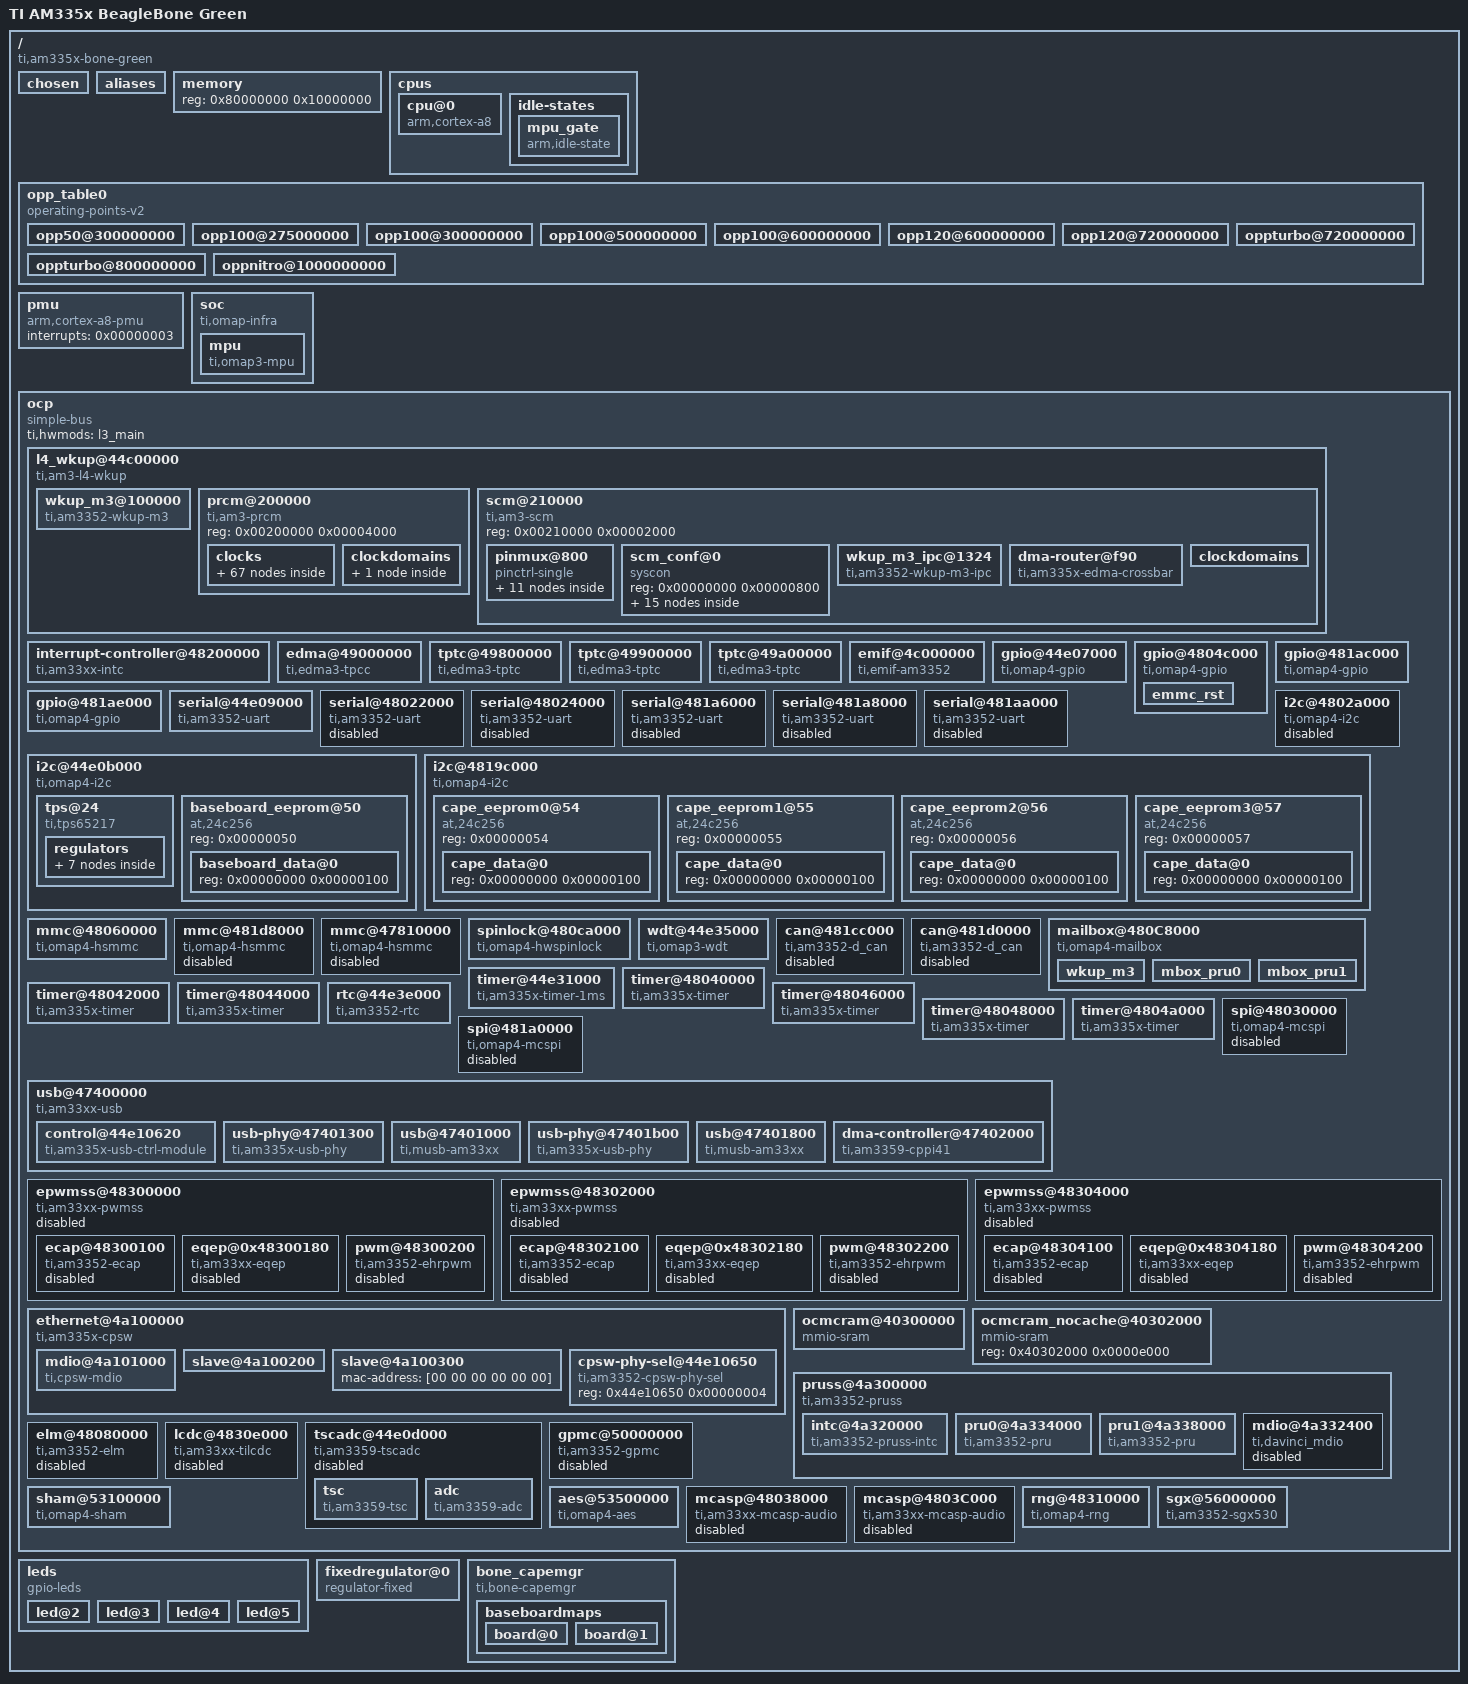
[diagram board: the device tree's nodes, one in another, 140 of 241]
/dts-v1/;
// magic:		0xd00dfeed
// totalsize:		0xd51f (54559)
// off_dt_struct:	0x38
// off_dt_strings:	0xc508
// off_mem_rsvmap:	0x28
// version:		17
// last_comp_version:	16
// boot_cpuid_phys:	0x0
// size_dt_strings:	0x1017
// size_dt_struct:	0xc4d0

/ {
    #address-cells = <0x00000001>;
    #size-cells = <0x00000001>;
    compatible = "ti,am335x-bone-green", "ti,am335x-bone-black", "ti,am335x-bone", "ti,am33xx";
    interrupt-parent = <0x00000001>;
    model = "TI AM335x BeagleBone Green";
    chosen {
    };
    aliases {
        i2c0 = "/ocp/i2c@44e0b000";
        i2c1 = "/ocp/i2c@4802a000";
        i2c2 = "/ocp/i2c@4819c000";
        serial0 = "/ocp/serial@44e09000";
        serial1 = "/ocp/serial@48022000";
        serial2 = "/ocp/serial@48024000";
        serial3 = "/ocp/serial@481a6000";
        serial4 = "/ocp/serial@481a8000";
        serial5 = "/ocp/serial@481aa000";
        d_can0 = "/ocp/can@481cc000";
        d_can1 = "/ocp/can@481d0000";
        usb0 = "/ocp/usb@47400000/usb@47401000";
        usb1 = "/ocp/usb@47400000/usb@47401800";
        phy0 = "/ocp/usb@47400000/usb-phy@47401300";
        phy1 = "/ocp/usb@47400000/usb-phy@47401b00";
        ethernet0 = "/ocp/ethernet@4a100000/slave@4a100200";
        ethernet1 = "/ocp/ethernet@4a100000/slave@4a100300";
    };
    memory {
        device_type = "memory";
        reg = <0x80000000 0x10000000>;
    };
    cpus {
        #address-cells = <0x00000001>;
        #size-cells = <0x00000000>;
        cpu@0 {
            compatible = "arm,cortex-a8";
            enable-method = "ti,am3352";
            device_type = "cpu";
            reg = <0x00000000>;
            operating-points-v2 = <0x00000002>;
            ti,syscon-efuse = <0x00000003 0x000007fc 0x00001fff 0x00000000>;
            ti,syscon-rev = <0x00000003 0x00000600>;
            clocks = <0x00000004>;
            clock-names = "cpu";
            clock-latency = <0x000493e0>;
            cpu-idle-states = <0x00000005>;
            cpu0-supply = <0x00000006>;
        };
        idle-states {
            mpu_gate {
                compatible = "arm,idle-state";
                entry-latency-us = <0x00000028>;
                exit-latency-us = <0x0000005a>;
                min-residency-us = <0x0000012c>;
                ti,idle-wkup-m3;
                linux,phandle = <0x00000005>;
                phandle = <0x00000005>;
            };
        };
    };
    opp_table0 {
        compatible = "operating-points-v2";
        linux,phandle = <0x00000002>;
        phandle = <0x00000002>;
        opp50@300000000 {
            opp-hz = <0x00000000 0x11e1a300>;
            opp-microvolt = <0x000e7ef0 0x000e34b8 0x000ec928>;
            opp-supported-hw = <0x00000006 0x00000010>;
            opp-suspend;
        };
        opp100@275000000 {
            opp-hz = <0x00000000 0x10642ac0>;
            opp-microvolt = <0x0010c8e0 0x001072f0 0x00111ed0>;
            opp-supported-hw = <0x00000001 0x000000ff>;
            opp-suspend;
        };
        opp100@300000000 {
            opp-hz = <0x00000000 0x11e1a300>;
            opp-microvolt = <0x0010c8e0 0x001072f0 0x00111ed0>;
            opp-supported-hw = <0x00000006 0x00000020>;
            opp-suspend;
        };
        opp100@500000000 {
            opp-hz = <0x00000000 0x1dcd6500>;
            opp-microvolt = <0x0010c8e0 0x001072f0 0x00111ed0>;
            opp-supported-hw = <0x00000001 0x0000ffff>;
        };
        opp100@600000000 {
            opp-hz = <0x00000000 0x23c34600>;
            opp-microvolt = <0x0010c8e0 0x001072f0 0x00111ed0>;
            opp-supported-hw = <0x00000006 0x00000040>;
        };
        opp120@600000000 {
            opp-hz = <0x00000000 0x23c34600>;
            opp-microvolt = <0x00124f80 0x0011f1c0 0x0012ad40>;
            opp-supported-hw = <0x00000001 0x0000ffff>;
        };
        opp120@720000000 {
            opp-hz = <0x00000000 0x2aea5400>;
            opp-microvolt = <0x00124f80 0x0011f1c0 0x0012ad40>;
            opp-supported-hw = <0x00000006 0x00000080>;
        };
        oppturbo@720000000 {
            opp-hz = <0x00000000 0x2aea5400>;
            opp-microvolt = <0x001339e0 0x0012d770 0x00139c50>;
            opp-supported-hw = <0x00000001 0x0000ffff>;
        };
        oppturbo@800000000 {
            opp-hz = <0x00000000 0x2faf0800>;
            opp-microvolt = <0x001339e0 0x0012d770 0x00139c50>;
            opp-supported-hw = <0x00000006 0x00000100>;
        };
        oppnitro@1000000000 {
            opp-hz = <0x00000000 0x3b9aca00>;
            opp-microvolt = <0x001437c8 0x0013d044 0x00149f4c>;
            opp-supported-hw = <0x00000006 0x00000100>;
        };
    };
    pmu {
        compatible = "arm,cortex-a8-pmu";
        interrupts = <0x00000003>;
    };
    soc {
        compatible = "ti,omap-infra";
        mpu {
            compatible = "ti,omap3-mpu";
            ti,hwmods = "mpu";
            sram = <0x00000007>;
        };
    };
    ocp {
        compatible = "simple-bus";
        #address-cells = <0x00000001>;
        #size-cells = <0x00000001>;
        ranges;
        ti,hwmods = "l3_main";
        linux,phandle = <0x00000051>;
        phandle = <0x00000051>;
        l4_wkup@44c00000 {
            compatible = "ti,am3-l4-wkup", "simple-bus";
            #address-cells = <0x00000001>;
            #size-cells = <0x00000001>;
            ranges = <0x00000000 0x44c00000 0x00280000>;
            linux,phandle = <0x00000052>;
            phandle = <0x00000052>;
            wkup_m3@100000 {
                compatible = "ti,am3352-wkup-m3";
                reg = <0x00100000 0x00004000 0x00180000 0x00002000>;
                reg-names = "umem", "dmem";
                ti,hwmods = "wkup_m3";
                ti,pm-firmware = "am335x-pm-firmware.elf";
                linux,phandle = <0x00000029>;
                phandle = <0x00000029>;
            };
            prcm@200000 {
                compatible = "ti,am3-prcm";
                reg = <0x00200000 0x00004000>;
                linux,phandle = <0x00000053>;
                phandle = <0x00000053>;
                clocks {
                    #address-cells = <0x00000001>;
                    #size-cells = <0x00000000>;
                    linux,phandle = <0x00000054>;
                    phandle = <0x00000054>;
                    clk_32768_ck {
                        #clock-cells = <0x00000000>;
                        compatible = "fixed-clock";
                        clock-frequency = <0x00008000>;
                        linux,phandle = <0x00000018>;
                        phandle = <0x00000018>;
                    };
                    clk_rc32k_ck {
                        #clock-cells = <0x00000000>;
                        compatible = "fixed-clock";
                        clock-frequency = <0x00007d00>;
                        linux,phandle = <0x00000017>;
                        phandle = <0x00000017>;
                    };
                    virt_19200000_ck {
                        #clock-cells = <0x00000000>;
                        compatible = "fixed-clock";
                        clock-frequency = <0x0124f800>;
                        linux,phandle = <0x00000024>;
                        phandle = <0x00000024>;
                    };
                    virt_24000000_ck {
                        #clock-cells = <0x00000000>;
                        compatible = "fixed-clock";
                        clock-frequency = <0x016e3600>;
                        linux,phandle = <0x00000025>;
                        phandle = <0x00000025>;
                    };
                    virt_25000000_ck {
                        #clock-cells = <0x00000000>;
                        compatible = "fixed-clock";
                        clock-frequency = <0x017d7840>;
                        linux,phandle = <0x00000026>;
                        phandle = <0x00000026>;
                    };
                    virt_26000000_ck {
                        #clock-cells = <0x00000000>;
                        compatible = "fixed-clock";
                        clock-frequency = <0x018cba80>;
                        linux,phandle = <0x00000027>;
                        phandle = <0x00000027>;
                    };
                    tclkin_ck {
                        #clock-cells = <0x00000000>;
                        compatible = "fixed-clock";
                        clock-frequency = <0x00b71b00>;
                        linux,phandle = <0x00000016>;
                        phandle = <0x00000016>;
                    };
                    dpll_core_ck {
                        #clock-cells = <0x00000000>;
                        compatible = "ti,am3-dpll-core-clock";
                        clocks = <0x00000008 0x00000008>;
                        reg = <0x00000490 0x0000045c 0x00000468>;
                        linux,phandle = <0x00000009>;
                        phandle = <0x00000009>;
                    };
                    dpll_core_x2_ck {
                        #clock-cells = <0x00000000>;
                        compatible = "ti,am3-dpll-x2-clock";
                        clocks = <0x00000009>;
                        linux,phandle = <0x0000000a>;
                        phandle = <0x0000000a>;
                    };
                    dpll_core_m4_ck {
                        #clock-cells = <0x00000000>;
                        compatible = "ti,divider-clock";
                        clocks = <0x0000000a>;
                        ti,max-div = <0x0000001f>;
                        reg = <0x00000480>;
                        ti,index-starts-at-one;
                        linux,phandle = <0x00000012>;
                        phandle = <0x00000012>;
                    };
                    dpll_core_m5_ck {
                        #clock-cells = <0x00000000>;
                        compatible = "ti,divider-clock";
                        clocks = <0x0000000a>;
                        ti,max-div = <0x0000001f>;
                        reg = <0x00000484>;
                        ti,index-starts-at-one;
                        linux,phandle = <0x0000001a>;
                        phandle = <0x0000001a>;
                    };
                    dpll_core_m6_ck {
                        #clock-cells = <0x00000000>;
                        compatible = "ti,divider-clock";
                        clocks = <0x0000000a>;
                        ti,max-div = <0x0000001f>;
                        reg = <0x000004d8>;
                        ti,index-starts-at-one;
                        linux,phandle = <0x00000055>;
                        phandle = <0x00000055>;
                    };
                    dpll_mpu_ck {
                        #clock-cells = <0x00000000>;
                        compatible = "ti,am3-dpll-clock";
                        clocks = <0x00000008 0x00000008>;
                        reg = <0x00000488 0x00000420 0x0000042c>;
                        linux,phandle = <0x00000004>;
                        phandle = <0x00000004>;
                    };
                    dpll_mpu_m2_ck {
                        #clock-cells = <0x00000000>;
                        compatible = "ti,divider-clock";
                        clocks = <0x00000004>;
                        ti,max-div = <0x0000001f>;
                        reg = <0x000004a8>;
                        ti,index-starts-at-one;
                        linux,phandle = <0x00000056>;
                        phandle = <0x00000056>;
                    };
                    dpll_ddr_ck {
                        #clock-cells = <0x00000000>;
                        compatible = "ti,am3-dpll-no-gate-clock";
                        clocks = <0x00000008 0x00000008>;
                        reg = <0x00000494 0x00000434 0x00000440>;
                        linux,phandle = <0x0000000b>;
                        phandle = <0x0000000b>;
                    };
                    dpll_ddr_m2_ck {
                        #clock-cells = <0x00000000>;
                        compatible = "ti,divider-clock";
                        clocks = <0x0000000b>;
                        ti,max-div = <0x0000001f>;
                        reg = <0x000004a0>;
                        ti,index-starts-at-one;
                        linux,phandle = <0x0000000c>;
                        phandle = <0x0000000c>;
                    };
                    dpll_ddr_m2_div2_ck {
                        #clock-cells = <0x00000000>;
                        compatible = "fixed-factor-clock";
                        clocks = <0x0000000c>;
                        clock-mult = <0x00000001>;
                        clock-div = <0x00000002>;
                        linux,phandle = <0x00000057>;
                        phandle = <0x00000057>;
                    };
                    dpll_disp_ck {
                        #clock-cells = <0x00000000>;
                        compatible = "ti,am3-dpll-no-gate-clock";
                        clocks = <0x00000008 0x00000008>;
                        reg = <0x00000498 0x00000448 0x00000454>;
                        linux,phandle = <0x0000000d>;
                        phandle = <0x0000000d>;
                    };
                    dpll_disp_m2_ck {
                        #clock-cells = <0x00000000>;
                        compatible = "ti,divider-clock";
                        clocks = <0x0000000d>;
                        ti,max-div = <0x0000001f>;
                        reg = <0x000004a4>;
                        ti,index-starts-at-one;
                        ti,set-rate-parent;
                        linux,phandle = <0x00000014>;
                        phandle = <0x00000014>;
                    };
                    dpll_per_ck {
                        #clock-cells = <0x00000000>;
                        compatible = "ti,am3-dpll-no-gate-j-type-clock";
                        clocks = <0x00000008 0x00000008>;
                        reg = <0x0000048c 0x00000470 0x0000049c>;
                        linux,phandle = <0x0000000e>;
                        phandle = <0x0000000e>;
                    };
                    dpll_per_m2_ck {
                        #clock-cells = <0x00000000>;
                        compatible = "ti,divider-clock";
                        clocks = <0x0000000e>;
                        ti,max-div = <0x0000001f>;
                        reg = <0x000004ac>;
                        ti,index-starts-at-one;
                        linux,phandle = <0x0000000f>;
                        phandle = <0x0000000f>;
                    };
                    dpll_per_m2_div4_wkupdm_ck {
                        #clock-cells = <0x00000000>;
                        compatible = "fixed-factor-clock";
                        clocks = <0x0000000f>;
                        clock-mult = <0x00000001>;
                        clock-div = <0x00000004>;
                        linux,phandle = <0x00000058>;
                        phandle = <0x00000058>;
                    };
                    dpll_per_m2_div4_ck {
                        #clock-cells = <0x00000000>;
                        compatible = "fixed-factor-clock";
                        clocks = <0x0000000f>;
                        clock-mult = <0x00000001>;
                        clock-div = <0x00000004>;
                        linux,phandle = <0x00000059>;
                        phandle = <0x00000059>;
                    };
                    cefuse_fck {
                        #clock-cells = <0x00000000>;
                        compatible = "ti,gate-clock";
                        clocks = <0x00000008>;
                        ti,bit-shift = <0x00000001>;
                        reg = <0x00000a20>;
                        linux,phandle = <0x0000005a>;
                        phandle = <0x0000005a>;
                    };
                    clk_24mhz {
                        #clock-cells = <0x00000000>;
                        compatible = "fixed-factor-clock";
                        clocks = <0x0000000f>;
                        clock-mult = <0x00000001>;
                        clock-div = <0x00000008>;
                        linux,phandle = <0x00000010>;
                        phandle = <0x00000010>;
                    };
                    clkdiv32k_ck {
                        #clock-cells = <0x00000000>;
                        compatible = "fixed-factor-clock";
                        clocks = <0x00000010>;
                        clock-mult = <0x00000001>;
                        clock-div = <0x000002dc>;
                        linux,phandle = <0x00000011>;
                        phandle = <0x00000011>;
                    };
                    clkdiv32k_ick {
                        #clock-cells = <0x00000000>;
                        compatible = "ti,gate-clock";
                        clocks = <0x00000011>;
                        ti,bit-shift = <0x00000001>;
                        reg = <0x0000014c>;
                        linux,phandle = <0x00000015>;
                        phandle = <0x00000015>;
                    };
                    l3_gclk {
                        #clock-cells = <0x00000000>;
                        compatible = "fixed-factor-clock";
                        clocks = <0x00000012>;
                        clock-mult = <0x00000001>;
                        clock-div = <0x00000001>;
                        linux,phandle = <0x00000013>;
                        phandle = <0x00000013>;
                    };
                    pruss_ocp_gclk {
                        #clock-cells = <0x00000000>;
                        compatible = "ti,mux-clock";
                        clocks = <0x00000013 0x00000014>;
                        reg = <0x00000530>;
                        linux,phandle = <0x0000005b>;
                        phandle = <0x0000005b>;
                    };
                    mmu_fck {
                        #clock-cells = <0x00000000>;
                        compatible = "ti,gate-clock";
                        clocks = <0x00000012>;
                        ti,bit-shift = <0x00000001>;
                        reg = <0x00000914>;
                        linux,phandle = <0x0000005c>;
                        phandle = <0x0000005c>;
                    };
                    timer1_fck {
                        #clock-cells = <0x00000000>;
                        compatible = "ti,mux-clock";
                        clocks = <0x00000008 0x00000015 0x00000016 0x00000017 0x00000018>;
                        reg = <0x00000528>;
                        linux,phandle = <0x0000005d>;
                        phandle = <0x0000005d>;
                    };
                    timer2_fck {
                        #clock-cells = <0x00000000>;
                        compatible = "ti,mux-clock";
                        clocks = <0x00000016 0x00000008 0x00000015>;
                        reg = <0x00000508>;
                        linux,phandle = <0x0000005e>;
                        phandle = <0x0000005e>;
                    };
                    timer3_fck {
                        #clock-cells = <0x00000000>;
                        compatible = "ti,mux-clock";
                        clocks = <0x00000016 0x00000008 0x00000015>;
                        reg = <0x0000050c>;
                        linux,phandle = <0x0000005f>;
                        phandle = <0x0000005f>;
                    };
                    timer4_fck {
                        #clock-cells = <0x00000000>;
                        compatible = "ti,mux-clock";
                        clocks = <0x00000016 0x00000008 0x00000015>;
                        reg = <0x00000510>;
                        linux,phandle = <0x00000060>;
                        phandle = <0x00000060>;
                    };
                    timer5_fck {
                        #clock-cells = <0x00000000>;
                        compatible = "ti,mux-clock";
                        clocks = <0x00000016 0x00000008 0x00000015>;
                        reg = <0x00000518>;
                        linux,phandle = <0x00000061>;
                        phandle = <0x00000061>;
                    };
                    timer6_fck {
                        #clock-cells = <0x00000000>;
                        compatible = "ti,mux-clock";
                        clocks = <0x00000016 0x00000008 0x00000015>;
                        reg = <0x0000051c>;
                        linux,phandle = <0x00000062>;
                        phandle = <0x00000062>;
                    };
                    timer7_fck {
                        #clock-cells = <0x00000000>;
                        compatible = "ti,mux-clock";
                        clocks = <0x00000016 0x00000008 0x00000015>;
                        reg = <0x00000504>;
                        linux,phandle = <0x00000063>;
                        phandle = <0x00000063>;
                    };
                    usbotg_fck {
                        #clock-cells = <0x00000000>;
                        compatible = "ti,gate-clock";
                        clocks = <0x0000000e>;
                        ti,bit-shift = <0x00000008>;
                        reg = <0x0000047c>;
                        linux,phandle = <0x00000064>;
                        phandle = <0x00000064>;
                    };
                    dpll_core_m4_div2_ck {
                        #clock-cells = <0x00000000>;
                        compatible = "fixed-factor-clock";
                        clocks = <0x00000012>;
                        clock-mult = <0x00000001>;
                        clock-div = <0x00000002>;
                        linux,phandle = <0x00000019>;
                        phandle = <0x00000019>;
                    };
                    ieee5000_fck {
                        #clock-cells = <0x00000000>;
                        compatible = "ti,gate-clock";
                        clocks = <0x00000019>;
                        ti,bit-shift = <0x00000001>;
                        reg = <0x000000e4>;
                        linux,phandle = <0x00000065>;
                        phandle = <0x00000065>;
                    };
                    wdt1_fck {
                        #clock-cells = <0x00000000>;
                        compatible = "ti,mux-clock";
                        clocks = <0x00000017 0x00000015>;
                        reg = <0x00000538>;
                        linux,phandle = <0x00000066>;
                        phandle = <0x00000066>;
                    };
                    l4_rtc_gclk {
                        #clock-cells = <0x00000000>;
                        compatible = "fixed-factor-clock";
                        clocks = <0x00000012>;
                        clock-mult = <0x00000001>;
                        clock-div = <0x00000002>;
                        linux,phandle = <0x00000067>;
                        phandle = <0x00000067>;
                    };
                    l4hs_gclk {
                        #clock-cells = <0x00000000>;
                        compatible = "fixed-factor-clock";
                        clocks = <0x00000012>;
                        clock-mult = <0x00000001>;
                        clock-div = <0x00000001>;
                        linux,phandle = <0x00000068>;
                        phandle = <0x00000068>;
                    };
                    l3s_gclk {
                        #clock-cells = <0x00000000>;
                        compatible = "fixed-factor-clock";
                        clocks = <0x00000019>;
                        clock-mult = <0x00000001>;
                        clock-div = <0x00000001>;
                        linux,phandle = <0x00000069>;
                        phandle = <0x00000069>;
                    };
                    l4fw_gclk {
                        #clock-cells = <0x00000000>;
                        compatible = "fixed-factor-clock";
                        clocks = <0x00000019>;
                        clock-mult = <0x00000001>;
                        clock-div = <0x00000001>;
                        linux,phandle = <0x0000006a>;
                        phandle = <0x0000006a>;
                    };
                    l4ls_gclk {
                        #clock-cells = <0x00000000>;
                        compatible = "fixed-factor-clock";
                        clocks = <0x00000019>;
                        clock-mult = <0x00000001>;
                        clock-div = <0x00000001>;
                        linux,phandle = <0x00000028>;
                        phandle = <0x00000028>;
                    };
                    sysclk_div_ck {
                        #clock-cells = <0x00000000>;
                        compatible = "fixed-factor-clock";
                        clocks = <0x00000012>;
                        clock-mult = <0x00000001>;
                        clock-div = <0x00000001>;
                        linux,phandle = <0x0000006b>;
                        phandle = <0x0000006b>;
                    };
                    cpsw_125mhz_gclk {
                        #clock-cells = <0x00000000>;
                        compatible = "fixed-factor-clock";
                        clocks = <0x0000001a>;
                        clock-mult = <0x00000001>;
                        clock-div = <0x00000002>;
                        linux,phandle = <0x00000040>;
                        phandle = <0x00000040>;
                    };
                    cpsw_cpts_rft_clk {
                        #clock-cells = <0x00000000>;
                        compatible = "ti,mux-clock";
                        clocks = <0x0000001a 0x00000012>;
                        reg = <0x00000520>;
                        linux,phandle = <0x00000041>;
                        phandle = <0x00000041>;
                    };
                    gpio0_dbclk_mux_ck {
                        #clock-cells = <0x00000000>;
                        compatible = "ti,mux-clock";
                        clocks = <0x00000017 0x00000018 0x00000015>;
                        reg = <0x0000053c>;
                        linux,phandle = <0x0000001b>;
                        phandle = <0x0000001b>;
                    };
                    gpio0_dbclk {
                        #clock-cells = <0x00000000>;
                        compatible = "ti,gate-clock";
                        clocks = <0x0000001b>;
                        ti,bit-shift = <0x00000012>;
                        reg = <0x00000408>;
                        linux,phandle = <0x0000006c>;
                        phandle = <0x0000006c>;
                    };
                    gpio1_dbclk {
                        #clock-cells = <0x00000000>;
                        compatible = "ti,gate-clock";
                        clocks = <0x00000015>;
                        ti,bit-shift = <0x00000012>;
                        reg = <0x000000ac>;
                        linux,phandle = <0x0000006d>;
                        phandle = <0x0000006d>;
                    };
                    gpio2_dbclk {
                        #clock-cells = <0x00000000>;
                        compatible = "ti,gate-clock";
                        clocks = <0x00000015>;
                        ti,bit-shift = <0x00000012>;
                        reg = <0x000000b0>;
                        linux,phandle = <0x0000006e>;
                        phandle = <0x0000006e>;
                    };
                    gpio3_dbclk {
                        #clock-cells = <0x00000000>;
                        compatible = "ti,gate-clock";
                        clocks = <0x00000015>;
                        ti,bit-shift = <0x00000012>;
                        reg = <0x000000b4>;
                        linux,phandle = <0x0000006f>;
                        phandle = <0x0000006f>;
                    };
                    lcd_gclk {
                        #clock-cells = <0x00000000>;
                        compatible = "ti,mux-clock";
                        clocks = <0x00000014 0x0000001a 0x0000000f>;
                        reg = <0x00000534>;
                        ti,set-rate-parent;
                        linux,phandle = <0x0000001d>;
                        phandle = <0x0000001d>;
                    };
                    mmc_clk {
                        #clock-cells = <0x00000000>;
                        compatible = "fixed-factor-clock";
                        clocks = <0x0000000f>;
                        clock-mult = <0x00000001>;
                        clock-div = <0x00000002>;
                        linux,phandle = <0x00000070>;
                        phandle = <0x00000070>;
                    };
                    gfx_fclk_clksel_ck {
                        #clock-cells = <0x00000000>;
                        compatible = "ti,mux-clock";
                        clocks = <0x00000012 0x0000000f>;
                        ti,bit-shift = <0x00000001>;
                        reg = <0x0000052c>;
                        linux,phandle = <0x0000001c>;
                        phandle = <0x0000001c>;
                    };
                    gfx_fck_div_ck {
                        #clock-cells = <0x00000000>;
                        compatible = "ti,divider-clock";
                        clocks = <0x0000001c>;
                        reg = <0x0000052c>;
                        ti,max-div = <0x00000002>;
                        linux,phandle = <0x00000048>;
                        phandle = <0x00000048>;
                    };
                    sysclkout_pre_ck {
                        #clock-cells = <0x00000000>;
                        compatible = "ti,mux-clock";
                        clocks = <0x00000018 0x00000013 0x0000000c 0x0000000f 0x0000001d>;
                        reg = <0x00000700>;
                        linux,phandle = <0x0000001e>;
                        phandle = <0x0000001e>;
                    };
                    clkout2_div_ck {
                        #clock-cells = <0x00000000>;
                        compatible = "ti,divider-clock";
                        clocks = <0x0000001e>;
                        ti,bit-shift = <0x00000003>;
                        ti,max-div = <0x00000008>;
                        reg = <0x00000700>;
                        linux,phandle = <0x00000023>;
                        phandle = <0x00000023>;
                    };
                    dbg_sysclk_ck {
                        #clock-cells = <0x00000000>;
                        compatible = "ti,gate-clock";
                        clocks = <0x00000008>;
                        ti,bit-shift = <0x00000013>;
                        reg = <0x00000414>;
                        linux,phandle = <0x0000001f>;
                        phandle = <0x0000001f>;
                    };
                    dbg_clka_ck {
                        #clock-cells = <0x00000000>;
                        compatible = "ti,gate-clock";
                        clocks = <0x00000012>;
                        ti,bit-shift = <0x0000001e>;
                        reg = <0x00000414>;
                        linux,phandle = <0x00000020>;
                        phandle = <0x00000020>;
                    };
                    stm_pmd_clock_mux_ck {
                        #clock-cells = <0x00000000>;
                        compatible = "ti,mux-clock";
                        clocks = <0x0000001f 0x00000020>;
                        ti,bit-shift = <0x00000016>;
                        reg = <0x00000414>;
                        linux,phandle = <0x00000021>;
                        phandle = <0x00000021>;
                    };
                    trace_pmd_clk_mux_ck {
                        #clock-cells = <0x00000000>;
                        compatible = "ti,mux-clock";
                        clocks = <0x0000001f 0x00000020>;
                        ti,bit-shift = <0x00000014>;
                        reg = <0x00000414>;
                        linux,phandle = <0x00000022>;
                        phandle = <0x00000022>;
                    };
                    stm_clk_div_ck {
                        #clock-cells = <0x00000000>;
                        compatible = "ti,divider-clock";
                        clocks = <0x00000021>;
                        ti,bit-shift = <0x0000001b>;
                        ti,max-div = <0x00000040>;
                        reg = <0x00000414>;
                        ti,index-power-of-two;
                        linux,phandle = <0x00000071>;
                        phandle = <0x00000071>;
                    };
                    trace_clk_div_ck {
                        #clock-cells = <0x00000000>;
                        compatible = "ti,divider-clock";
                        clocks = <0x00000022>;
                        ti,bit-shift = <0x00000018>;
                        ti,max-div = <0x00000040>;
                        reg = <0x00000414>;
                        ti,index-power-of-two;
                        linux,phandle = <0x00000072>;
                        phandle = <0x00000072>;
                    };
                    clkout2_ck {
                        #clock-cells = <0x00000000>;
                        compatible = "ti,gate-clock";
                        clocks = <0x00000023>;
                        ti,bit-shift = <0x00000007>;
                        reg = <0x00000700>;
                        linux,phandle = <0x00000073>;
                        phandle = <0x00000073>;
                    };
                };
                clockdomains {
                    linux,phandle = <0x00000074>;
                    phandle = <0x00000074>;
                    clk_24mhz_clkdm {
                        compatible = "ti,clockdomain";
                        clocks = <0x00000015>;
                        linux,phandle = <0x00000075>;
                        phandle = <0x00000075>;
                    };
                };
            };
            scm@210000 {
                compatible = "ti,am3-scm", "simple-bus";
                reg = <0x00210000 0x00002000>;
                #address-cells = <0x00000001>;
                #size-cells = <0x00000001>;
                ranges = <0x00000000 0x00210000 0x00002000>;
                linux,phandle = <0x00000076>;
                phandle = <0x00000076>;
                pinmux@800 {
                    compatible = "pinctrl-single";
                    reg = <0x00000800 0x00000238>;
                    #address-cells = <0x00000001>;
                    #size-cells = <0x00000000>;
                    pinctrl-single,register-width = <0x00000020>;
                    pinctrl-single,function-mask = <0x0000007f>;
                    linux,phandle = <0x00000077>;
                    phandle = <0x00000077>;
                    user_leds_default {
                        pinctrl-single,pins = <0x00000054 0x00000007 0x00000058 0x00000017 0x0000005c 0x00000007 0x00000060 0x00000017>;
                        linux,phandle = <0x00000049>;
                        phandle = <0x00000049>;
                    };
                    user_leds_sleep {
                        pinctrl-single,pins = <0x00000054 0x00000027 0x00000058 0x00000027 0x0000005c 0x00000027 0x00000060 0x00000027>;
                        linux,phandle = <0x0000004a>;
                        phandle = <0x0000004a>;
                    };
                    pinmux_i2c0_pins {
                        pinctrl-single,pins = <0x00000188 0x00000030 0x0000018c 0x00000030>;
                        linux,phandle = <0x00000031>;
                        phandle = <0x00000031>;
                    };
                    pinmux_i2c2_pins {
                        //pinctrl-single,pins = <0x00000178 0x00000033 0x0000017c 0x00000033>; //whooooops XXX
                        pinctrl-single,pins = <0x00000178 0x00000017 0x0000017c 0x0000002F>; //whooooops XXX
                        linux,phandle = <0x00000032>;
                        phandle = <0x00000032>;
                    };
                    pinmux_uart0_pins {
                        pinctrl-single,pins = <0x00000170 0x00000030 0x00000174 0x00000000>;
                        linux,phandle = <0x00000030>;
                        phandle = <0x00000030>;
                    };
                    cpsw_default {
                        pinctrl-single,pins = <0x00000108 0x00000028 0x0000010c 0x00000028 0x00000110 0x00000030 0x00000114 0x00000000 0x00000118 0x00000030 0x0000011c 0x00000000 0x00000120 0x00000000 0x00000124 0x00000000 0x00000128 0x00000000 0x0000012c 0x00000030 0x00000130 0x00000030 0x00000134 0x00000030 0x00000138 0x00000030 0x0000013c 0x00000030 0x00000140 0x00000030>;
                        linux,phandle = <0x00000042>;
                        phandle = <0x00000042>;
                    };
                    cpsw_sleep {
                        pinctrl-single,pins = <0x00000108 0x00000027 0x0000010c 0x00000027 0x00000110 0x00000027 0x00000114 0x00000027 0x00000118 0x00000027 0x0000011c 0x00000027 0x00000120 0x00000027 0x00000124 0x00000027 0x00000128 0x00000027 0x0000012c 0x00000027 0x00000130 0x00000027 0x00000134 0x00000027 0x00000138 0x00000027 0x0000013c 0x00000027 0x00000140 0x00000027>;
                        linux,phandle = <0x00000043>;
                        phandle = <0x00000043>;
                    };
                    davinci_mdio_default {
                        pinctrl-single,pins = <0x00000148 0x00000030 0x0000014c 0x00000010>;
                        linux,phandle = <0x00000044>;
                        phandle = <0x00000044>;
                    };
                    davinci_mdio_sleep {
                        pinctrl-single,pins = <0x00000148 0x00000027 0x0000014c 0x00000027>;
                        linux,phandle = <0x00000045>;
                        phandle = <0x00000045>;
                    };
                    pinmux_mmc1_pins {
                        pinctrl-single,pins = <0x00000160 0x0000002f>;
                        linux,phandle = <0x00000034>;
                        phandle = <0x00000034>;
                    };
                    pinmux_emmc_pins {
                        pinctrl-single,pins = <0x00000080 0x00000032 0x00000084 0x00000032 0x00000000 0x00000031 0x00000004 0x00000031 0x00000008 0x00000031 0x0000000c 0x00000031 0x00000010 0x00000031 0x00000014 0x00000031 0x00000018 0x00000031 0x0000001c 0x00000031>;
                        linux,phandle = <0x00000078>;
                        phandle = <0x00000078>;
                    };
                };
                scm_conf@0 {
                    compatible = "syscon";
                    reg = <0x00000000 0x00000800>;
                    #address-cells = <0x00000001>;
                    #size-cells = <0x00000001>;
                    linux,phandle = <0x00000003>;
                    phandle = <0x00000003>;
                    clocks {
                        #address-cells = <0x00000001>;
                        #size-cells = <0x00000000>;
                        linux,phandle = <0x00000079>;
                        phandle = <0x00000079>;
                        sys_clkin_ck {
                            #clock-cells = <0x00000000>;
                            compatible = "ti,mux-clock";
                            clocks = <0x00000024 0x00000025 0x00000026 0x00000027>;
                            ti,bit-shift = <0x00000016>;
                            reg = <0x00000040>;
                            linux,phandle = <0x00000008>;
                            phandle = <0x00000008>;
                        };
                        adc_tsc_fck {
                            #clock-cells = <0x00000000>;
                            compatible = "fixed-factor-clock";
                            clocks = <0x00000008>;
                            clock-mult = <0x00000001>;
                            clock-div = <0x00000001>;
                            linux,phandle = <0x0000007a>;
                            phandle = <0x0000007a>;
                        };
                        dcan0_fck {
                            #clock-cells = <0x00000000>;
                            compatible = "fixed-factor-clock";
                            clocks = <0x00000008>;
                            clock-mult = <0x00000001>;
                            clock-div = <0x00000001>;
                            linux,phandle = <0x00000037>;
                            phandle = <0x00000037>;
                        };
                        dcan1_fck {
                            #clock-cells = <0x00000000>;
                            compatible = "fixed-factor-clock";
                            clocks = <0x00000008>;
                            clock-mult = <0x00000001>;
                            clock-div = <0x00000001>;
                            linux,phandle = <0x00000038>;
                            phandle = <0x00000038>;
                        };
                        mcasp0_fck {
                            #clock-cells = <0x00000000>;
                            compatible = "fixed-factor-clock";
                            clocks = <0x00000008>;
                            clock-mult = <0x00000001>;
                            clock-div = <0x00000001>;
                            linux,phandle = <0x0000007b>;
                            phandle = <0x0000007b>;
                        };
                        mcasp1_fck {
                            #clock-cells = <0x00000000>;
                            compatible = "fixed-factor-clock";
                            clocks = <0x00000008>;
                            clock-mult = <0x00000001>;
                            clock-div = <0x00000001>;
                            linux,phandle = <0x0000007c>;
                            phandle = <0x0000007c>;
                        };
                        smartreflex0_fck {
                            #clock-cells = <0x00000000>;
                            compatible = "fixed-factor-clock";
                            clocks = <0x00000008>;
                            clock-mult = <0x00000001>;
                            clock-div = <0x00000001>;
                            linux,phandle = <0x0000007d>;
                            phandle = <0x0000007d>;
                        };
                        smartreflex1_fck {
                            #clock-cells = <0x00000000>;
                            compatible = "fixed-factor-clock";
                            clocks = <0x00000008>;
                            clock-mult = <0x00000001>;
                            clock-div = <0x00000001>;
                            linux,phandle = <0x0000007e>;
                            phandle = <0x0000007e>;
                        };
                        sha0_fck {
                            #clock-cells = <0x00000000>;
                            compatible = "fixed-factor-clock";
                            clocks = <0x00000008>;
                            clock-mult = <0x00000001>;
                            clock-div = <0x00000001>;
                            linux,phandle = <0x0000007f>;
                            phandle = <0x0000007f>;
                        };
                        aes0_fck {
                            #clock-cells = <0x00000000>;
                            compatible = "fixed-factor-clock";
                            clocks = <0x00000008>;
                            clock-mult = <0x00000001>;
                            clock-div = <0x00000001>;
                            linux,phandle = <0x00000080>;
                            phandle = <0x00000080>;
                        };
                        rng_fck {
                            #clock-cells = <0x00000000>;
                            compatible = "fixed-factor-clock";
                            clocks = <0x00000008>;
                            clock-mult = <0x00000001>;
                            clock-div = <0x00000001>;
                            linux,phandle = <0x00000081>;
                            phandle = <0x00000081>;
                        };
                        ehrpwm0_tbclk@44e10664 {
                            #clock-cells = <0x00000000>;
                            compatible = "ti,gate-clock";
                            clocks = <0x00000028>;
                            ti,bit-shift = <0x00000000>;
                            reg = <0x00000664>;
                            linux,phandle = <0x0000003d>;
                            phandle = <0x0000003d>;
                        };
                        ehrpwm1_tbclk@44e10664 {
                            #clock-cells = <0x00000000>;
                            compatible = "ti,gate-clock";
                            clocks = <0x00000028>;
                            ti,bit-shift = <0x00000001>;
                            reg = <0x00000664>;
                            linux,phandle = <0x0000003e>;
                            phandle = <0x0000003e>;
                        };
                        ehrpwm2_tbclk@44e10664 {
                            #clock-cells = <0x00000000>;
                            compatible = "ti,gate-clock";
                            clocks = <0x00000028>;
                            ti,bit-shift = <0x00000002>;
                            reg = <0x00000664>;
                            linux,phandle = <0x0000003f>;
                            phandle = <0x0000003f>;
                        };
                    };
                };
                wkup_m3_ipc@1324 {
                    compatible = "ti,am3352-wkup-m3-ipc";
                    reg = <0x00001324 0x00000024>;
                    interrupts = <0x0000004e>;
                    ti,rproc = <0x00000029>;
                    mboxes = <0x0000002a 0x0000002b>;
                    ti,scale-data-fw = "am335x-bone-scale-data.bin";
                    linux,phandle = <0x00000082>;
                    phandle = <0x00000082>;
                };
                dma-router@f90 {
                    compatible = "ti,am335x-edma-crossbar";
                    reg = <0x00000f90 0x00000040>;
                    #dma-cells = <0x00000003>;
                    dma-requests = <0x00000020>;
                    dma-masters = <0x0000002c>;
                    linux,phandle = <0x00000033>;
                    phandle = <0x00000033>;
                };
                clockdomains {
                    linux,phandle = <0x00000083>;
                    phandle = <0x00000083>;
                };
            };
        };
        interrupt-controller@48200000 {
            compatible = "ti,am33xx-intc";
            interrupt-controller;
            #interrupt-cells = <0x00000001>;
            reg = <0x48200000 0x00001000>;
            linux,phandle = <0x00000001>;
            phandle = <0x00000001>;
        };
        edma@49000000 {
            compatible = "ti,edma3-tpcc";
            ti,hwmods = "tpcc";
            reg = <0x49000000 0x00010000>;
            reg-names = "edma3_cc";
            interrupts = <0x0000000c 0x0000000d 0x0000000e>;
            interrupt-names = "edma3_ccint", "emda3_mperr", "edma3_ccerrint";
            dma-requests = <0x00000040>;
            #dma-cells = <0x00000002>;
            ti,tptcs = <0x0000002d 0x00000007 0x0000002e 0x00000005 0x0000002f 0x00000000>;
            ti,edma-memcpy-channels = <0x00000014 0x00000015>;
            linux,phandle = <0x0000002c>;
            phandle = <0x0000002c>;
        };
        tptc@49800000 {
            compatible = "ti,edma3-tptc";
            ti,hwmods = "tptc0";
            reg = <0x49800000 0x00100000>;
            interrupts = <0x00000070>;
            interrupt-names = "edma3_tcerrint";
            linux,phandle = <0x0000002d>;
            phandle = <0x0000002d>;
        };
        tptc@49900000 {
            compatible = "ti,edma3-tptc";
            ti,hwmods = "tptc1";
            reg = <0x49900000 0x00100000>;
            interrupts = <0x00000071>;
            interrupt-names = "edma3_tcerrint";
            linux,phandle = <0x0000002e>;
            phandle = <0x0000002e>;
        };
        tptc@49a00000 {
            compatible = "ti,edma3-tptc";
            ti,hwmods = "tptc2";
            reg = <0x49a00000 0x00100000>;
            interrupts = <0x00000072>;
            interrupt-names = "edma3_tcerrint";
            linux,phandle = <0x0000002f>;
            phandle = <0x0000002f>;
        };
        emif@4c000000 {
            compatible = "ti,emif-am3352";
            reg = <0x4c000000 0x00001000>;
            sram = <0x00000007>;
            linux,phandle = <0x00000084>;
            phandle = <0x00000084>;
        };
        gpio@44e07000 {
            compatible = "ti,omap4-gpio";
            ti,hwmods = "gpio1";
            gpio-controller;
            #gpio-cells = <0x00000002>;
            interrupt-controller;
            #interrupt-cells = <0x00000002>;
            reg = <0x44e07000 0x00001000>;
            interrupts = <0x00000060>;
            linux,phandle = <0x00000035>;
            phandle = <0x00000035>;
        };
        gpio@4804c000 {
            compatible = "ti,omap4-gpio";
            ti,hwmods = "gpio2";
            gpio-controller;
            #gpio-cells = <0x00000002>;
            interrupt-controller;
            #interrupt-cells = <0x00000002>;
            reg = <0x4804c000 0x00001000>;
            interrupts = <0x00000062>;
            linux,phandle = <0x0000004b>;
            phandle = <0x0000004b>;
            emmc_rst {
                gpio-hog;
                gpios = <0x00000014 0x00000000>;
                output-high;
                line-name = "EMMC ResetN";
            };
        };
        gpio@481ac000 {
            compatible = "ti,omap4-gpio";
            ti,hwmods = "gpio3";
            gpio-controller;
            #gpio-cells = <0x00000002>;
            interrupt-controller;
            #interrupt-cells = <0x00000002>;
            reg = <0x481ac000 0x00001000>;
            interrupts = <0x00000020>;
            linux,phandle = <0x00000085>;
            phandle = <0x00000085>;
        };
        gpio@481ae000 {
            compatible = "ti,omap4-gpio";
            ti,hwmods = "gpio4";
            gpio-controller;
            #gpio-cells = <0x00000002>;
            interrupt-controller;
            #interrupt-cells = <0x00000002>;
            reg = <0x481ae000 0x00001000>;
            interrupts = <0x0000003e>;
            linux,phandle = <0x00000086>;
            phandle = <0x00000086>;
        };
        serial@44e09000 {
            compatible = "ti,am3352-uart", "ti,omap3-uart";
            ti,hwmods = "uart1";
            clock-frequency = <0x02dc6c00>;
            reg = <0x44e09000 0x00002000>;
            interrupts = <0x00000048>;
            status = "okay";
            dmas = <0x0000002c 0x0000001a 0x00000000 0x0000002c 0x0000001b 0x00000000>;
            dma-names = "tx", "rx";
            pinctrl-names = "default";
            pinctrl-0 = <0x00000030>;
            linux,phandle = <0x00000087>;
            phandle = <0x00000087>;
        };
        serial@48022000 {
            compatible = "ti,am3352-uart", "ti,omap3-uart";
            ti,hwmods = "uart2";
            clock-frequency = <0x02dc6c00>;
            reg = <0x48022000 0x00002000>;
            interrupts = <0x00000049>;
            status = "disabled";
            dmas = <0x0000002c 0x0000001c 0x00000000 0x0000002c 0x0000001d 0x00000000>;
            dma-names = "tx", "rx";
            linux,phandle = <0x00000088>;
            phandle = <0x00000088>;
        };
        serial@48024000 {
            compatible = "ti,am3352-uart", "ti,omap3-uart";
            ti,hwmods = "uart3";
            clock-frequency = <0x02dc6c00>;
            reg = <0x48024000 0x00002000>;
            interrupts = <0x0000004a>;
            status = "disabled";
            dmas = <0x0000002c 0x0000001e 0x00000000 0x0000002c 0x0000001f 0x00000000>;
            dma-names = "tx", "rx";
            linux,phandle = <0x00000089>;
            phandle = <0x00000089>;
        };
        serial@481a6000 {
            compatible = "ti,am3352-uart", "ti,omap3-uart";
            ti,hwmods = "uart4";
            clock-frequency = <0x02dc6c00>;
            reg = <0x481a6000 0x00002000>;
            interrupts = <0x0000002c>;
            status = "disabled";
            linux,phandle = <0x0000008a>;
            phandle = <0x0000008a>;
        };
        serial@481a8000 {
            compatible = "ti,am3352-uart", "ti,omap3-uart";
            ti,hwmods = "uart5";
            clock-frequency = <0x02dc6c00>;
            reg = <0x481a8000 0x00002000>;
            interrupts = <0x0000002d>;
            status = "disabled";
            linux,phandle = <0x0000008b>;
            phandle = <0x0000008b>;
        };
        serial@481aa000 {
            compatible = "ti,am3352-uart", "ti,omap3-uart";
            ti,hwmods = "uart6";
            clock-frequency = <0x02dc6c00>;
            reg = <0x481aa000 0x00002000>;
            interrupts = <0x0000002e>;
            status = "disabled";
            linux,phandle = <0x0000008c>;
            phandle = <0x0000008c>;
        };
        i2c@44e0b000 {
            compatible = "ti,omap4-i2c";
            #address-cells = <0x00000001>;
            #size-cells = <0x00000000>;
            ti,hwmods = "i2c1";
            reg = <0x44e0b000 0x00001000>;
            interrupts = <0x00000046>;
            status = "okay";
            pinctrl-names = "default";
            pinctrl-0 = <0x00000031>;
            clock-frequency = <0x00061a80>;
            linux,phandle = <0x0000008d>;
            phandle = <0x0000008d>;
            tps@24 {
                reg = <0x00000024>;
                compatible = "ti,tps65217";
                ti,pmic-shutdown-controller;
                interrupt-parent = <0x00000001>;
                interrupts = <0x00000007>;
                linux,phandle = <0x0000008e>;
                phandle = <0x0000008e>;
                regulators {
                    #address-cells = <0x00000001>;
                    #size-cells = <0x00000000>;
                    regulator@0 {
                        reg = <0x00000000>;
                        regulator-compatible = "dcdc1";
                        regulator-name = "vdds_dpr";
                        regulator-always-on;
                        linux,phandle = <0x0000008f>;
                        phandle = <0x0000008f>;
                    };
                    regulator@1 {
                        reg = <0x00000001>;
                        regulator-compatible = "dcdc2";
                        regulator-name = "vdd_mpu";
                        regulator-min-microvolt = <0x000e1d48>;
                        regulator-max-microvolt = <0x00149f4c>;
                        regulator-boot-on;
                        regulator-always-on;
                        linux,phandle = <0x00000006>;
                        phandle = <0x00000006>;
                    };
                    regulator@2 {
                        reg = <0x00000002>;
                        regulator-compatible = "dcdc3";
                        regulator-name = "vdd_core";
                        regulator-min-microvolt = <0x000e1d48>;
                        regulator-max-microvolt = <0x00118c30>;
                        regulator-boot-on;
                        regulator-always-on;
                        linux,phandle = <0x00000090>;
                        phandle = <0x00000090>;
                    };
                    regulator@3 {
                        reg = <0x00000003>;
                        regulator-compatible = "ldo1";
                        regulator-name = "vio,vrtc,vdds";
                        regulator-always-on;
                        linux,phandle = <0x00000091>;
                        phandle = <0x00000091>;
                    };
                    regulator@4 {
                        reg = <0x00000004>;
                        regulator-compatible = "ldo2";
                        regulator-name = "vdd_3v3aux";
                        regulator-always-on;
                        linux,phandle = <0x00000092>;
                        phandle = <0x00000092>;
                    };
                    regulator@5 {
                        reg = <0x00000005>;
                        regulator-compatible = "ldo3";
                        regulator-name = "vdd_1v8";
                        regulator-always-on;
                        regulator-min-microvolt = <0x001b7740>;
                        regulator-max-microvolt = <0x001b7740>;
                        linux,phandle = <0x00000093>;
                        phandle = <0x00000093>;
                    };
                    regulator@6 {
                        reg = <0x00000006>;
                        regulator-compatible = "ldo4";
                        regulator-name = "vdd_3v3a";
                        regulator-always-on;
                        linux,phandle = <0x00000094>;
                        phandle = <0x00000094>;
                    };
                };
            };
            baseboard_eeprom@50 {
                compatible = "at,24c256";
                reg = <0x00000050>;
                #address-cells = <0x00000001>;
                #size-cells = <0x00000001>;
                linux,phandle = <0x00000095>;
                phandle = <0x00000095>;
                baseboard_data@0 {
                    reg = <0x00000000 0x00000100>;
                    linux,phandle = <0x0000004c>;
                    phandle = <0x0000004c>;
                };
            };
        };
        i2c@4802a000 {
            compatible = "ti,omap4-i2c";
            #address-cells = <0x00000001>;
            #size-cells = <0x00000000>;
            ti,hwmods = "i2c2";
            reg = <0x4802a000 0x00001000>;
            interrupts = <0x00000047>;
            status = "disabled";
            linux,phandle = <0x00000096>;
            phandle = <0x00000096>;
        };
        i2c@4819c000 {
            compatible = "ti,omap4-i2c";
            #address-cells = <0x00000001>;
            #size-cells = <0x00000000>;
            ti,hwmods = "i2c3";
            reg = <0x4819c000 0x00001000>;
            interrupts = <0x0000001e>;
            status = "okay";            // ???xxx
            pinctrl-names = "default";
            //pinctrl-0 = <0x00000032>;     //  ??? xxx
            clock-frequency = <0x000186a0>;
            linux,phandle = <0x00000097>;
            phandle = <0x00000097>;
            cape_eeprom0@54 {
                compatible = "at,24c256";
                reg = <0x00000054>;
                #address-cells = <0x00000001>;
                #size-cells = <0x00000001>;
                linux,phandle = <0x00000098>;
                phandle = <0x00000098>;
                cape_data@0 {
                    reg = <0x00000000 0x00000100>;
                    linux,phandle = <0x0000004d>;
                    phandle = <0x0000004d>;
                };
            };
            cape_eeprom1@55 {
                compatible = "at,24c256";
                reg = <0x00000055>;
                #address-cells = <0x00000001>;
                #size-cells = <0x00000001>;
                linux,phandle = <0x00000099>;
                phandle = <0x00000099>;
                cape_data@0 {
                    reg = <0x00000000 0x00000100>;
                    linux,phandle = <0x0000004e>;
                    phandle = <0x0000004e>;
                };
            };
            cape_eeprom2@56 {
                compatible = "at,24c256";
                reg = <0x00000056>;
                #address-cells = <0x00000001>;
                #size-cells = <0x00000001>;
                linux,phandle = <0x0000009a>;
                phandle = <0x0000009a>;
                cape_data@0 {
                    reg = <0x00000000 0x00000100>;
                    linux,phandle = <0x0000004f>;
                    phandle = <0x0000004f>;
                };
            };
            cape_eeprom3@57 {
                compatible = "at,24c256";
                reg = <0x00000057>;
                #address-cells = <0x00000001>;
                #size-cells = <0x00000001>;
                linux,phandle = <0x0000009b>;
                phandle = <0x0000009b>;
                cape_data@0 {
                    reg = <0x00000000 0x00000100>;
                    linux,phandle = <0x00000050>;
                    phandle = <0x00000050>;
                };
            };
        };
        mmc@48060000 {
            compatible = "ti,omap4-hsmmc";
            ti,hwmods = "mmc1";
            ti,dual-volt;
            ti,needs-special-reset;
            ti,needs-special-hs-handling;
            dmas = <0x00000033 0x00000018 0x00000000 0x00000000 0x00000033 0x00000019 0x00000000 0x00000000>;
            dma-names = "tx", "rx";
            interrupts = <0x00000040>;
            interrupt-parent = <0x00000001>;
            reg = <0x48060000 0x00001000>;
            status = "okay";
            bus-width = <0x00000004>;
            pinctrl-names = "default";
            pinctrl-0 = <0x00000034>;
            cd-gpios = <0x00000035 0x00000006 0x00000001>;
            vmmc-supply = <0x00000036>;
            linux,phandle = <0x0000009c>;
            phandle = <0x0000009c>;
        };
        mmc@481d8000 {
            compatible = "ti,omap4-hsmmc";
            ti,hwmods = "mmc2";
            ti,needs-special-reset;
            dmas = <0x0000002c 0x00000002 0x00000000 0x0000002c 0x00000003 0x00000000>;
            dma-names = "tx", "rx";
            interrupts = <0x0000001c>;
            interrupt-parent = <0x00000001>;
            reg = <0x481d8000 0x00001000>;
            status = "disabled";
            linux,phandle = <0x0000009d>;
            phandle = <0x0000009d>;
        };
        mmc@47810000 {
            compatible = "ti,omap4-hsmmc";
            ti,hwmods = "mmc3";
            ti,needs-special-reset;
            interrupts = <0x0000001d>;
            interrupt-parent = <0x00000001>;
            reg = <0x47810000 0x00001000>;
            status = "disabled";
            linux,phandle = <0x0000009e>;
            phandle = <0x0000009e>;
        };
        spinlock@480ca000 {
            compatible = "ti,omap4-hwspinlock";
            reg = <0x480ca000 0x00001000>;
            ti,hwmods = "spinlock";
            #hwlock-cells = <0x00000001>;
            linux,phandle = <0x0000009f>;
            phandle = <0x0000009f>;
        };
        wdt@44e35000 {
            compatible = "ti,omap3-wdt";
            ti,hwmods = "wd_timer2";
            reg = <0x44e35000 0x00001000>;
            interrupts = <0x0000005b>;
            linux,phandle = <0x000000a0>;
            phandle = <0x000000a0>;
        };
        can@481cc000 {
            compatible = "ti,am3352-d_can";
            ti,hwmods = "d_can0";
            reg = <0x481cc000 0x00002000>;
            clocks = <0x00000037>;
            clock-names = "fck";
            syscon-raminit = <0x00000003 0x00000644 0x00000000>;
            interrupts = <0x00000034>;
            status = "disabled";
            linux,phandle = <0x000000a1>;
            phandle = <0x000000a1>;
        };
        can@481d0000 {
            compatible = "ti,am3352-d_can";
            ti,hwmods = "d_can1";
            reg = <0x481d0000 0x00002000>;
            clocks = <0x00000038>;
            clock-names = "fck";
            syscon-raminit = <0x00000003 0x00000644 0x00000001>;
            interrupts = <0x00000037>;
            status = "disabled";
            linux,phandle = <0x000000a2>;
            phandle = <0x000000a2>;
        };
        mailbox@480C8000 {
            compatible = "ti,omap4-mailbox";
            reg = <0x480c8000 0x00000200>;
            interrupts = <0x0000004d>;
            ti,hwmods = "mailbox";
            #mbox-cells = <0x00000001>;
            ti,mbox-num-users = <0x00000004>;
            ti,mbox-num-fifos = <0x00000008>;
            linux,phandle = <0x0000002a>;
            phandle = <0x0000002a>;
            wkup_m3 {
                ti,mbox-send-noirq;
                ti,mbox-tx = <0x00000000 0x00000000 0x00000000>;
                ti,mbox-rx = <0x00000000 0x00000000 0x00000003>;
                linux,phandle = <0x0000002b>;
                phandle = <0x0000002b>;
            };
            mbox_pru0 {
                ti,mbox-tx = <0x00000002 0x00000000 0x00000000>;
                ti,mbox-rx = <0x00000003 0x00000000 0x00000000>;
                linux,phandle = <0x000000a3>;
                phandle = <0x000000a3>;
            };
            mbox_pru1 {
                ti,mbox-tx = <0x00000004 0x00000000 0x00000000>;
                ti,mbox-rx = <0x00000005 0x00000000 0x00000000>;
                linux,phandle = <0x000000a4>;
                phandle = <0x000000a4>;
            };
        };
        timer@44e31000 {
            compatible = "ti,am335x-timer-1ms";
            reg = <0x44e31000 0x00000400>;
            interrupts = <0x00000043>;
            ti,hwmods = "timer1";
            ti,timer-alwon;
            linux,phandle = <0x000000a5>;
            phandle = <0x000000a5>;
        };
        timer@48040000 {
            compatible = "ti,am335x-timer";
            reg = <0x48040000 0x00000400>;
            interrupts = <0x00000044>;
            ti,hwmods = "timer2";
            linux,phandle = <0x000000a6>;
            phandle = <0x000000a6>;
        };
        timer@48042000 {
            compatible = "ti,am335x-timer";
            reg = <0x48042000 0x00000400>;
            interrupts = <0x00000045>;
            ti,hwmods = "timer3";
            linux,phandle = <0x000000a7>;
            phandle = <0x000000a7>;
        };
        timer@48044000 {
            compatible = "ti,am335x-timer";
            reg = <0x48044000 0x00000400>;
            interrupts = <0x0000005c>;
            ti,hwmods = "timer4";
            ti,timer-pwm;
            linux,phandle = <0x000000a8>;
            phandle = <0x000000a8>;
        };
        timer@48046000 {
            compatible = "ti,am335x-timer";
            reg = <0x48046000 0x00000400>;
            interrupts = <0x0000005d>;
            ti,hwmods = "timer5";
            ti,timer-pwm;
            linux,phandle = <0x000000a9>;
            phandle = <0x000000a9>;
        };
        timer@48048000 {
            compatible = "ti,am335x-timer";
            reg = <0x48048000 0x00000400>;
            interrupts = <0x0000005e>;
            ti,hwmods = "timer6";
            ti,timer-pwm;
            linux,phandle = <0x000000aa>;
            phandle = <0x000000aa>;
        };
        timer@4804a000 {
            compatible = "ti,am335x-timer";
            reg = <0x4804a000 0x00000400>;
            interrupts = <0x0000005f>;
            ti,hwmods = "timer7";
            ti,timer-pwm;
            linux,phandle = <0x000000ab>;
            phandle = <0x000000ab>;
        };
        rtc@44e3e000 {
            compatible = "ti,am3352-rtc", "ti,da830-rtc";
            reg = <0x44e3e000 0x00001000>;
            interrupts = <0x0000004b 0x0000004c>;
            ti,hwmods = "rtc";
            clocks = <0x00000018 0x00000015>;
            clock-names = "ext-clk", "int-clk";
            system-power-controller;
            linux,phandle = <0x000000ac>;
            phandle = <0x000000ac>;
        };
        spi@48030000 {
            compatible = "ti,omap4-mcspi";
            #address-cells = <0x00000001>;
            #size-cells = <0x00000000>;
            reg = <0x48030000 0x00000400>;
            interrupts = <0x00000041>;
            ti,spi-num-cs = <0x00000002>;
            ti,hwmods = "spi0";
            dmas = <0x0000002c 0x00000010 0x00000000 0x0000002c 0x00000011 0x00000000 0x0000002c 0x00000012 0x00000000 0x0000002c 0x00000013 0x00000000>;
            dma-names = "tx0", "rx0", "tx1", "rx1";
            status = "disabled";
            linux,phandle = <0x000000ad>;
            phandle = <0x000000ad>;
        };
        spi@481a0000 {
            compatible = "ti,omap4-mcspi";
            #address-cells = <0x00000001>;
            #size-cells = <0x00000000>;
            reg = <0x481a0000 0x00000400>;
            interrupts = <0x0000007d>;
            ti,spi-num-cs = <0x00000002>;
            ti,hwmods = "spi1";
            dmas = <0x0000002c 0x0000002a 0x00000000 0x0000002c 0x0000002b 0x00000000 0x0000002c 0x0000002c 0x00000000 0x0000002c 0x0000002d 0x00000000>;
            dma-names = "tx0", "rx0", "tx1", "rx1";
            status = "disabled";
            linux,phandle = <0x000000ae>;
            phandle = <0x000000ae>;
        };
        usb@47400000 {
            compatible = "ti,am33xx-usb";
            reg = <0x47400000 0x00001000>;
            ranges;
            #address-cells = <0x00000001>;
            #size-cells = <0x00000001>;
            ti,hwmods = "usb_otg_hs";
            status = "okay";
            linux,phandle = <0x000000af>;
            phandle = <0x000000af>;
            control@44e10620 {
                compatible = "ti,am335x-usb-ctrl-module";
                reg = <0x44e10620 0x00000010 0x44e10648 0x00000004>;
                reg-names = "phy_ctrl", "wakeup";
                status = "okay";
                linux,phandle = <0x00000039>;
                phandle = <0x00000039>;
            };
            usb-phy@47401300 {
                compatible = "ti,am335x-usb-phy";
                reg = <0x47401300 0x00000100>;
                reg-names = "phy";
                status = "okay";
                ti,ctrl_mod = <0x00000039>;
                linux,phandle = <0x0000003a>;
                phandle = <0x0000003a>;
            };
            usb@47401000 {
                compatible = "ti,musb-am33xx";
                status = "okay";
                reg = <0x47401400 0x00000400 0x47401000 0x00000200>;
                reg-names = "mc", "control";
                interrupts = <0x00000012>;
                interrupt-names = "mc";
                dr_mode = "peripheral";
                mentor,multipoint = <0x00000001>;
                mentor,num-eps = <0x00000010>;
                mentor,ram-bits = <0x0000000c>;
                mentor,power = <0x000001f4>;
                phys = <0x0000003a>;
                dmas = <0x0000003b 0x00000000 0x00000000 0x0000003b 0x00000001 0x00000000 0x0000003b 0x00000002 0x00000000 0x0000003b 0x00000003 0x00000000 0x0000003b 0x00000004 0x00000000 0x0000003b 0x00000005 0x00000000 0x0000003b 0x00000006 0x00000000 0x0000003b 0x00000007 0x00000000 0x0000003b 0x00000008 0x00000000 0x0000003b 0x00000009 0x00000000 0x0000003b 0x0000000a 0x00000000 0x0000003b 0x0000000b 0x00000000 0x0000003b 0x0000000c 0x00000000 0x0000003b 0x0000000d 0x00000000 0x0000003b 0x0000000e 0x00000000 0x0000003b 0x00000000 0x00000001 0x0000003b 0x00000001 0x00000001 0x0000003b 0x00000002 0x00000001 0x0000003b 0x00000003 0x00000001 0x0000003b 0x00000004 0x00000001 0x0000003b 0x00000005 0x00000001 0x0000003b 0x00000006 0x00000001 0x0000003b 0x00000007 0x00000001 0x0000003b 0x00000008 0x00000001 0x0000003b 0x00000009 0x00000001 0x0000003b 0x0000000a 0x00000001 0x0000003b 0x0000000b 0x00000001 0x0000003b 0x0000000c 0x00000001 0x0000003b 0x0000000d 0x00000001 0x0000003b 0x0000000e 0x00000001>;
                dma-names = "rx1", "rx2", "rx3", "rx4", "rx5", "rx6", "rx7", "rx8", "rx9", "rx10", "rx11", "rx12", "rx13", "rx14", "rx15", "tx1", "tx2", "tx3", "tx4", "tx5", "tx6", "tx7", "tx8", "tx9", "tx10", "tx11", "tx12", "tx13", "tx14", "tx15";
                linux,phandle = <0x000000b0>;
                phandle = <0x000000b0>;
            };
            usb-phy@47401b00 {
                compatible = "ti,am335x-usb-phy";
                reg = <0x47401b00 0x00000100>;
                reg-names = "phy";
                status = "okay";
                ti,ctrl_mod = <0x00000039>;
                linux,phandle = <0x0000003c>;
                phandle = <0x0000003c>;
            };
            usb@47401800 {
                compatible = "ti,musb-am33xx";
                status = "okay";
                reg = <0x47401c00 0x00000400 0x47401800 0x00000200>;
                reg-names = "mc", "control";
                interrupts = <0x00000013>;
                interrupt-names = "mc";
                dr_mode = "host";
                mentor,multipoint = <0x00000001>;
                mentor,num-eps = <0x00000010>;
                mentor,ram-bits = <0x0000000c>;
                mentor,power = <0x000001f4>;
                phys = <0x0000003c>;
                dmas = <0x0000003b 0x0000000f 0x00000000 0x0000003b 0x00000010 0x00000000 0x0000003b 0x00000011 0x00000000 0x0000003b 0x00000012 0x00000000 0x0000003b 0x00000013 0x00000000 0x0000003b 0x00000014 0x00000000 0x0000003b 0x00000015 0x00000000 0x0000003b 0x00000016 0x00000000 0x0000003b 0x00000017 0x00000000 0x0000003b 0x00000018 0x00000000 0x0000003b 0x00000019 0x00000000 0x0000003b 0x0000001a 0x00000000 0x0000003b 0x0000001b 0x00000000 0x0000003b 0x0000001c 0x00000000 0x0000003b 0x0000001d 0x00000000 0x0000003b 0x0000000f 0x00000001 0x0000003b 0x00000010 0x00000001 0x0000003b 0x00000011 0x00000001 0x0000003b 0x00000012 0x00000001 0x0000003b 0x00000013 0x00000001 0x0000003b 0x00000014 0x00000001 0x0000003b 0x00000015 0x00000001 0x0000003b 0x00000016 0x00000001 0x0000003b 0x00000017 0x00000001 0x0000003b 0x00000018 0x00000001 0x0000003b 0x00000019 0x00000001 0x0000003b 0x0000001a 0x00000001 0x0000003b 0x0000001b 0x00000001 0x0000003b 0x0000001c 0x00000001 0x0000003b 0x0000001d 0x00000001>;
                dma-names = "rx1", "rx2", "rx3", "rx4", "rx5", "rx6", "rx7", "rx8", "rx9", "rx10", "rx11", "rx12", "rx13", "rx14", "rx15", "tx1", "tx2", "tx3", "tx4", "tx5", "tx6", "tx7", "tx8", "tx9", "tx10", "tx11", "tx12", "tx13", "tx14", "tx15";
                linux,phandle = <0x000000b1>;
                phandle = <0x000000b1>;
            };
            dma-controller@47402000 {
                compatible = "ti,am3359-cppi41";
                reg = <0x47400000 0x00001000 0x47402000 0x00001000 0x47403000 0x00001000 0x47404000 0x00004000>;
                reg-names = "glue", "controller", "scheduler", "queuemgr";
                interrupts = <0x00000011>;
                interrupt-names = "glue";
                #dma-cells = <0x00000002>;
                #dma-channels = <0x0000001e>;
                #dma-requests = <0x00000100>;
                status = "okay";
                linux,phandle = <0x0000003b>;
                phandle = <0x0000003b>;
            };
        };
        epwmss@48300000 {
            compatible = "ti,am33xx-pwmss";
            reg = <0x48300000 0x00000010>;
            ti,hwmods = "epwmss0";
            #address-cells = <0x00000001>;
            #size-cells = <0x00000001>;
            status = "disabled";
            ranges = <0x48300100 0x48300100 0x00000080 0x48300180 0x48300180 0x00000080 0x48300200 0x48300200 0x00000080>;
            linux,phandle = <0x000000b2>;
            phandle = <0x000000b2>;
            ecap@48300100 {
                compatible = "ti,am3352-ecap", "ti,am33xx-ecap";
                #pwm-cells = <0x00000003>;
                reg = <0x48300100 0x00000080>;
                clocks = <0x00000028>;
                clock-names = "fck";
                interrupts = <0x0000001f>;
                interrupt-names = "ecap0";
                status = "disabled";
                linux,phandle = <0x000000b3>;
                phandle = <0x000000b3>;
            };
            eqep@0x48300180 {
                compatible = "ti,am33xx-eqep";
                reg = <0x48300180 0x00000080>;
                clocks = <0x00000028>;
                clock-names = "fck";
                interrupt-parent = <0x00000001>;
                interrupts = <0x0000004f>;
                status = "disabled";
                linux,phandle = <0x000000b4>;
                phandle = <0x000000b4>;
            };
            pwm@48300200 {
                compatible = "ti,am3352-ehrpwm", "ti,am33xx-ehrpwm";
                #pwm-cells = <0x00000003>;
                reg = <0x48300200 0x00000080>;
                clocks = <0x0000003d 0x00000028>;
                clock-names = "tbclk", "fck";
                status = "disabled";
                linux,phandle = <0x000000b5>;
                phandle = <0x000000b5>;
            };
        };
        epwmss@48302000 {
            compatible = "ti,am33xx-pwmss";
            reg = <0x48302000 0x00000010>;
            ti,hwmods = "epwmss1";
            #address-cells = <0x00000001>;
            #size-cells = <0x00000001>;
            status = "disabled";
            ranges = <0x48302100 0x48302100 0x00000080 0x48302180 0x48302180 0x00000080 0x48302200 0x48302200 0x00000080>;
            linux,phandle = <0x000000b6>;
            phandle = <0x000000b6>;
            ecap@48302100 {
                compatible = "ti,am3352-ecap", "ti,am33xx-ecap";
                #pwm-cells = <0x00000003>;
                reg = <0x48302100 0x00000080>;
                clocks = <0x00000028>;
                clock-names = "fck";
                interrupts = <0x0000002f>;
                interrupt-names = "ecap1";
                status = "disabled";
                linux,phandle = <0x000000b7>;
                phandle = <0x000000b7>;
            };
            eqep@0x48302180 {
                compatible = "ti,am33xx-eqep";
                reg = <0x48302180 0x00000080>;
                clocks = <0x00000028>;
                clock-names = "fck";
                interrupt-parent = <0x00000001>;
                interrupts = <0x00000058>;
                status = "disabled";
                linux,phandle = <0x000000b8>;
                phandle = <0x000000b8>;
            };
            pwm@48302200 {
                compatible = "ti,am3352-ehrpwm", "ti,am33xx-ehrpwm";
                #pwm-cells = <0x00000003>;
                reg = <0x48302200 0x00000080>;
                clocks = <0x0000003e 0x00000028>;
                clock-names = "tbclk", "fck";
                status = "disabled";
                linux,phandle = <0x000000b9>;
                phandle = <0x000000b9>;
            };
        };
        epwmss@48304000 {
            compatible = "ti,am33xx-pwmss";
            reg = <0x48304000 0x00000010>;
            ti,hwmods = "epwmss2";
            #address-cells = <0x00000001>;
            #size-cells = <0x00000001>;
            status = "disabled";
            ranges = <0x48304100 0x48304100 0x00000080 0x48304180 0x48304180 0x00000080 0x48304200 0x48304200 0x00000080>;
            linux,phandle = <0x000000ba>;
            phandle = <0x000000ba>;
            ecap@48304100 {
                compatible = "ti,am3352-ecap", "ti,am33xx-ecap";
                #pwm-cells = <0x00000003>;
                reg = <0x48304100 0x00000080>;
                clocks = <0x00000028>;
                clock-names = "fck";
                interrupts = <0x0000003d>;
                interrupt-names = "ecap2";
                status = "disabled";
                linux,phandle = <0x000000bb>;
                phandle = <0x000000bb>;
            };
            eqep@0x48304180 {
                compatible = "ti,am33xx-eqep";
                reg = <0x48304180 0x00000080>;
                clocks = <0x00000028>;
                clock-names = "fck";
                interrupt-parent = <0x00000001>;
                interrupts = <0x00000059>;
                status = "disabled";
                linux,phandle = <0x000000bc>;
                phandle = <0x000000bc>;
            };
            pwm@48304200 {
                compatible = "ti,am3352-ehrpwm", "ti,am33xx-ehrpwm";
                #pwm-cells = <0x00000003>;
                reg = <0x48304200 0x00000080>;
                clocks = <0x0000003f 0x00000028>;
                clock-names = "tbclk", "fck";
                status = "disabled";
                linux,phandle = <0x000000bd>;
                phandle = <0x000000bd>;
            };
        };
        ethernet@4a100000 {
            compatible = "ti,am335x-cpsw", "ti,cpsw";
            ti,hwmods = "cpgmac0";
            clocks = <0x00000040 0x00000041>;
            clock-names = "fck", "cpts";
            cpdma_channels = <0x00000008>;
            ale_entries = <0x00000400>;
            bd_ram_size = <0x00002000>;
            no_bd_ram = <0x00000000>;
            mac_control = <0x00000020>;
            slaves = <0x00000001>;
            active_slave = <0x00000000>;
            cpts_clock_mult = <0x80000000>;
            cpts_clock_shift = <0x0000001d>;
            reg = <0x4a100000 0x00000800 0x4a101200 0x00000100>;
            #address-cells = <0x00000001>;
            #size-cells = <0x00000001>;
            interrupt-parent = <0x00000001>;
            interrupts = <0x00000028 0x00000029 0x0000002a 0x0000002b>;
            ranges;
            syscon = <0x00000003>;
            status = "okay";
            pinctrl-names = "default", "sleep";
            pinctrl-0 = <0x00000042>;
            pinctrl-1 = <0x00000043>;
            linux,phandle = <0x000000be>;
            phandle = <0x000000be>;
            mdio@4a101000 {
                compatible = "ti,cpsw-mdio";
                #address-cells = <0x00000001>;
                #size-cells = <0x00000000>;
                ti,hwmods = "davinci_mdio";
                bus_freq = <0x000f4240>;
                reg = <0x4a101000 0x00000100>;
                status = "okay";
                pinctrl-names = "default", "sleep";
                pinctrl-0 = <0x00000044>;
                pinctrl-1 = <0x00000045>;
                linux,phandle = <0x00000046>;
                phandle = <0x00000046>;
            };
            slave@4a100200 {
                mac-address = [00 00 00 00 00 00];
                phy_id = <0x00000046 0x00000000>;
                phy-mode = "mii";
                linux,phandle = <0x000000bf>;
                phandle = <0x000000bf>;
            };
            slave@4a100300 {
                mac-address = [00 00 00 00 00 00];
                linux,phandle = <0x000000c0>;
                phandle = <0x000000c0>;
            };
            cpsw-phy-sel@44e10650 {
                compatible = "ti,am3352-cpsw-phy-sel";
                reg = <0x44e10650 0x00000004>;
                reg-names = "gmii-sel";
                linux,phandle = <0x000000c1>;
                phandle = <0x000000c1>;
            };
        };
        ocmcram@40300000 {
            compatible = "mmio-sram";
            reg = <0x40300000 0x00002000>;
            map-exec;
            linux,phandle = <0x00000007>;
            phandle = <0x00000007>;
        };
        ocmcram_nocache@40302000 {
            compatible = "mmio-sram";
            reg = <0x40302000 0x0000e000>;
            linux,phandle = <0x000000c2>;
            phandle = <0x000000c2>;
        };
        pruss@4a300000 {
            ti,hwmods = "pruss";
            status = "okay";
            compatible = "ti,am3352-pruss";
            reg = <0x4a300000 0x00002000 0x4a302000 0x00002000 0x4a310000 0x00003000 0x4a326000 0x00002000 0x4a32e000 0x0000031c 0x4a332000 0x00000058>;
            reg-names = "dram0", "dram1", "shrdram2", "cfg", "iep", "mii_rt";
            #address-cells = <0x00000001>;
            #size-cells = <0x00000001>;
            ranges;
            linux,phandle = <0x000000c3>;
            phandle = <0x000000c3>;
            intc@4a320000 {
                compatible = "ti,am3352-pruss-intc";
                reg = <0x4a320000 0x00002000>;
                reg-names = "intc";
                interrupts = <0x00000014 0x00000015 0x00000016 0x00000017 0x00000018 0x00000019 0x0000001a 0x0000001b>;
                interrupt-names = "host2", "host3", "host4", "host5", "host6", "host7", "host8", "host9";
                interrupt-controller;
                #interrupt-cells = <0x00000001>;
                linux,phandle = <0x00000047>;
                phandle = <0x00000047>;
            };
            pru0@4a334000 {
                compatible = "ti,am3352-pru";
                reg = <0x4a334000 0x00002000 0x4a322000 0x00000400 0x4a322400 0x00000100>;
                reg-names = "iram", "control", "debug";
                interrupt-parent = <0x00000047>;
                interrupts = <0x00000010 0x00000011>;
                interrupt-names = "vring", "kick";
                linux,phandle = <0x000000c4>;
                phandle = <0x000000c4>;
            };
            pru1@4a338000 {
                compatible = "ti,am3352-pru";
                reg = <0x4a338000 0x00002000 0x4a324000 0x00000400 0x4a324400 0x00000100>;
                reg-names = "iram", "control", "debug";
                interrupt-parent = <0x00000047>;
                interrupts = <0x00000012 0x00000013>;
                interrupt-names = "vring", "kick";
                linux,phandle = <0x000000c5>;
                phandle = <0x000000c5>;
            };
            mdio@4a332400 {
                compatible = "ti,davinci_mdio";
                reg = <0x4a332400 0x00000090>;
                clocks = <0x00000012>;
                clock-names = "fck";
                bus_freq = <0x000f4240>;
                #address-cells = <0x00000001>;
                #size-cells = <0x00000000>;
                status = "disabled";
                linux,phandle = <0x000000c6>;
                phandle = <0x000000c6>;
            };
        };
        elm@48080000 {
            compatible = "ti,am3352-elm";
            reg = <0x48080000 0x00002000>;
            interrupts = <0x00000004>;
            ti,hwmods = "elm";
            status = "disabled";
            linux,phandle = <0x000000c7>;
            phandle = <0x000000c7>;
        };
        lcdc@4830e000 {
            compatible = "ti,am33xx-tilcdc";
            reg = <0x4830e000 0x00001000>;
            interrupt-parent = <0x00000001>;
            interrupts = <0x00000024>;
            ti,hwmods = "lcdc";
            status = "disabled";
            linux,phandle = <0x000000c8>;
            phandle = <0x000000c8>;
        };
        tscadc@44e0d000 {
            compatible = "ti,am3359-tscadc";
            reg = <0x44e0d000 0x00001000>;
            interrupt-parent = <0x00000001>;
            interrupts = <0x00000010>;
            ti,hwmods = "adc_tsc";
            status = "disabled";
            linux,phandle = <0x000000c9>;
            phandle = <0x000000c9>;
            tsc {
                compatible = "ti,am3359-tsc";
            };
            adc {
                #io-channel-cells = <0x00000001>;
                compatible = "ti,am3359-adc";
                linux,phandle = <0x000000ca>;
                phandle = <0x000000ca>;
            };
        };
        gpmc@50000000 {
            compatible = "ti,am3352-gpmc";
            ti,hwmods = "gpmc";
            ti,no-idle-on-init;
            reg = <0x50000000 0x00002000>;
            interrupts = <0x00000064>;
            dmas = <0x0000002c 0x00000034 0x00000000>;
            dma-names = "rxtx";
            gpmc,num-cs = <0x00000007>;
            gpmc,num-waitpins = <0x00000002>;
            #address-cells = <0x00000002>;
            #size-cells = <0x00000001>;
            interrupt-controller;
            #interrupt-cells = <0x00000002>;
            gpio-controller;
            #gpio-cells = <0x00000002>;
            status = "disabled";
            linux,phandle = <0x000000cb>;
            phandle = <0x000000cb>;
        };
        sham@53100000 {
            compatible = "ti,omap4-sham";
            ti,hwmods = "sham";
            reg = <0x53100000 0x00000200>;
            interrupts = <0x0000006d>;
            dmas = <0x0000002c 0x00000024 0x00000000>;
            dma-names = "rx";
            status = "okay";
            linux,phandle = <0x000000cc>;
            phandle = <0x000000cc>;
        };
        aes@53500000 {
            compatible = "ti,omap4-aes";
            ti,hwmods = "aes";
            reg = <0x53500000 0x000000a0>;
            interrupts = <0x00000067>;
            dmas = <0x0000002c 0x00000006 0x00000000 0x0000002c 0x00000005 0x00000000>;
            dma-names = "tx", "rx";
            status = "okay";
            linux,phandle = <0x000000cd>;
            phandle = <0x000000cd>;
        };
        mcasp@48038000 {
            compatible = "ti,am33xx-mcasp-audio";
            ti,hwmods = "mcasp0";
            reg = <0x48038000 0x00002000 0x46000000 0x00400000>;
            reg-names = "mpu", "dat";
            interrupts = <0x00000050 0x00000051>;
            interrupt-names = "tx", "rx";
            status = "disabled";
            dmas = <0x0000002c 0x00000008 0x00000002 0x0000002c 0x00000009 0x00000002>;
            dma-names = "tx", "rx";
            linux,phandle = <0x000000ce>;
            phandle = <0x000000ce>;
        };
        mcasp@4803C000 {
            compatible = "ti,am33xx-mcasp-audio";
            ti,hwmods = "mcasp1";
            reg = <0x4803c000 0x00002000 0x46400000 0x00400000>;
            reg-names = "mpu", "dat";
            interrupts = <0x00000052 0x00000053>;
            interrupt-names = "tx", "rx";
            status = "disabled";
            dmas = <0x0000002c 0x0000000a 0x00000002 0x0000002c 0x0000000b 0x00000002>;
            dma-names = "tx", "rx";
            linux,phandle = <0x000000cf>;
            phandle = <0x000000cf>;
        };
        rng@48310000 {
            compatible = "ti,omap4-rng";
            ti,hwmods = "rng";
            reg = <0x48310000 0x00002000>;
            interrupts = <0x0000006f>;
            linux,phandle = <0x000000d0>;
            phandle = <0x000000d0>;
        };
        sgx@56000000 {
            compatible = "ti,am3352-sgx530", "img,sgx530";
            ti,hwmods = "gfx";
            reg = <0x56000000 0x00010000>;
            interrupts = <0x00000025>;
            clocks = <0x00000048>;
            clock-names = "fclk";
            status = "okay";
            linux,phandle = <0x000000d1>;
            phandle = <0x000000d1>;
        };
    };
    leds {
        pinctrl-names = "default", "sleep";
        pinctrl-0 = <0x00000049>;
        pinctrl-1 = <0x0000004a>;
        compatible = "gpio-leds";
        led@2 {
            label = "beaglebone:green:usr0";
            gpios = <0x0000004b 0x00000015 0x00000000>;
            linux,default-trigger = "heartbeat";
            default-state = "off";
        };
        led@3 {
            label = "beaglebone:green:usr1";
            gpios = <0x0000004b 0x00000016 0x00000000>;
            linux,default-trigger = "mmc0";
            default-state = "off";
        };
        led@4 {
            label = "beaglebone:green:usr2";
            gpios = <0x0000004b 0x00000017 0x00000000>;
            linux,default-trigger = "cpu0";
            default-state = "off";
        };
        led@5 {
            label = "beaglebone:green:usr3";
            gpios = <0x0000004b 0x00000018 0x00000000>;
            linux,default-trigger = "mmc1";
            default-state = "off";
        };
    };
    fixedregulator@0 {
        compatible = "regulator-fixed";
        regulator-name = "vmmcsd_fixed";
        regulator-min-microvolt = <0x00325aa0>;
        regulator-max-microvolt = <0x00325aa0>;
        linux,phandle = <0x00000036>;
        phandle = <0x00000036>;
    };
    bone_capemgr {
        compatible = "ti,bone-capemgr";
        status = "okay";
        nvmem-cells = <0x0000004c 0x0000004d 0x0000004e 0x0000004f 0x00000050>;
        nvmem-cell-names = "baseboard", "slot0", "slot1", "slot2", "slot3";
        #slots = <0x00000004>;
        baseboardmaps {
            board@0 {
                board-name = "A335BONE";
                compatible-name = "ti,beaglebone";
                linux,phandle = <0x000000d2>;
                phandle = <0x000000d2>;
            };
            board@1 {
                board-name = "A335BNLT";
                compatible-name = "ti,beaglebone-black";
                linux,phandle = <0x000000d3>;
                phandle = <0x000000d3>;
            };
        };
    };
    __symbols__ {
        mpu_gate = "/cpus/idle-states/mpu_gate";
        cpu0_opp_table = "/opp_table0";
        ocp = "/ocp";
        l4_wkup = "/ocp/l4_wkup@44c00000";
        wkup_m3 = "/ocp/l4_wkup@44c00000/wkup_m3@100000";
        prcm = "/ocp/l4_wkup@44c00000/prcm@200000";
        prcm_clocks = "/ocp/l4_wkup@44c00000/prcm@200000/clocks";
        clk_32768_ck = "/ocp/l4_wkup@44c00000/prcm@200000/clocks/clk_32768_ck";
        clk_rc32k_ck = "/ocp/l4_wkup@44c00000/prcm@200000/clocks/clk_rc32k_ck";
        virt_19200000_ck = "/ocp/l4_wkup@44c00000/prcm@200000/clocks/virt_19200000_ck";
        virt_24000000_ck = "/ocp/l4_wkup@44c00000/prcm@200000/clocks/virt_24000000_ck";
        virt_25000000_ck = "/ocp/l4_wkup@44c00000/prcm@200000/clocks/virt_25000000_ck";
        virt_26000000_ck = "/ocp/l4_wkup@44c00000/prcm@200000/clocks/virt_26000000_ck";
        tclkin_ck = "/ocp/l4_wkup@44c00000/prcm@200000/clocks/tclkin_ck";
        dpll_core_ck = "/ocp/l4_wkup@44c00000/prcm@200000/clocks/dpll_core_ck";
        dpll_core_x2_ck = "/ocp/l4_wkup@44c00000/prcm@200000/clocks/dpll_core_x2_ck";
        dpll_core_m4_ck = "/ocp/l4_wkup@44c00000/prcm@200000/clocks/dpll_core_m4_ck";
        dpll_core_m5_ck = "/ocp/l4_wkup@44c00000/prcm@200000/clocks/dpll_core_m5_ck";
        dpll_core_m6_ck = "/ocp/l4_wkup@44c00000/prcm@200000/clocks/dpll_core_m6_ck";
        dpll_mpu_ck = "/ocp/l4_wkup@44c00000/prcm@200000/clocks/dpll_mpu_ck";
        dpll_mpu_m2_ck = "/ocp/l4_wkup@44c00000/prcm@200000/clocks/dpll_mpu_m2_ck";
        dpll_ddr_ck = "/ocp/l4_wkup@44c00000/prcm@200000/clocks/dpll_ddr_ck";
        dpll_ddr_m2_ck = "/ocp/l4_wkup@44c00000/prcm@200000/clocks/dpll_ddr_m2_ck";
        dpll_ddr_m2_div2_ck = "/ocp/l4_wkup@44c00000/prcm@200000/clocks/dpll_ddr_m2_div2_ck";
        dpll_disp_ck = "/ocp/l4_wkup@44c00000/prcm@200000/clocks/dpll_disp_ck";
        dpll_disp_m2_ck = "/ocp/l4_wkup@44c00000/prcm@200000/clocks/dpll_disp_m2_ck";
        dpll_per_ck = "/ocp/l4_wkup@44c00000/prcm@200000/clocks/dpll_per_ck";
        dpll_per_m2_ck = "/ocp/l4_wkup@44c00000/prcm@200000/clocks/dpll_per_m2_ck";
        dpll_per_m2_div4_wkupdm_ck = "/ocp/l4_wkup@44c00000/prcm@200000/clocks/dpll_per_m2_div4_wkupdm_ck";
        dpll_per_m2_div4_ck = "/ocp/l4_wkup@44c00000/prcm@200000/clocks/dpll_per_m2_div4_ck";
        cefuse_fck = "/ocp/l4_wkup@44c00000/prcm@200000/clocks/cefuse_fck";
        clk_24mhz = "/ocp/l4_wkup@44c00000/prcm@200000/clocks/clk_24mhz";
        clkdiv32k_ck = "/ocp/l4_wkup@44c00000/prcm@200000/clocks/clkdiv32k_ck";
        clkdiv32k_ick = "/ocp/l4_wkup@44c00000/prcm@200000/clocks/clkdiv32k_ick";
        l3_gclk = "/ocp/l4_wkup@44c00000/prcm@200000/clocks/l3_gclk";
        pruss_ocp_gclk = "/ocp/l4_wkup@44c00000/prcm@200000/clocks/pruss_ocp_gclk";
        mmu_fck = "/ocp/l4_wkup@44c00000/prcm@200000/clocks/mmu_fck";
        timer1_fck = "/ocp/l4_wkup@44c00000/prcm@200000/clocks/timer1_fck";
        timer2_fck = "/ocp/l4_wkup@44c00000/prcm@200000/clocks/timer2_fck";
        timer3_fck = "/ocp/l4_wkup@44c00000/prcm@200000/clocks/timer3_fck";
        timer4_fck = "/ocp/l4_wkup@44c00000/prcm@200000/clocks/timer4_fck";
        timer5_fck = "/ocp/l4_wkup@44c00000/prcm@200000/clocks/timer5_fck";
        timer6_fck = "/ocp/l4_wkup@44c00000/prcm@200000/clocks/timer6_fck";
        timer7_fck = "/ocp/l4_wkup@44c00000/prcm@200000/clocks/timer7_fck";
        usbotg_fck = "/ocp/l4_wkup@44c00000/prcm@200000/clocks/usbotg_fck";
        dpll_core_m4_div2_ck = "/ocp/l4_wkup@44c00000/prcm@200000/clocks/dpll_core_m4_div2_ck";
        ieee5000_fck = "/ocp/l4_wkup@44c00000/prcm@200000/clocks/ieee5000_fck";
        wdt1_fck = "/ocp/l4_wkup@44c00000/prcm@200000/clocks/wdt1_fck";
        l4_rtc_gclk = "/ocp/l4_wkup@44c00000/prcm@200000/clocks/l4_rtc_gclk";
        l4hs_gclk = "/ocp/l4_wkup@44c00000/prcm@200000/clocks/l4hs_gclk";
        l3s_gclk = "/ocp/l4_wkup@44c00000/prcm@200000/clocks/l3s_gclk";
        l4fw_gclk = "/ocp/l4_wkup@44c00000/prcm@200000/clocks/l4fw_gclk";
        l4ls_gclk = "/ocp/l4_wkup@44c00000/prcm@200000/clocks/l4ls_gclk";
        sysclk_div_ck = "/ocp/l4_wkup@44c00000/prcm@200000/clocks/sysclk_div_ck";
        cpsw_125mhz_gclk = "/ocp/l4_wkup@44c00000/prcm@200000/clocks/cpsw_125mhz_gclk";
        cpsw_cpts_rft_clk = "/ocp/l4_wkup@44c00000/prcm@200000/clocks/cpsw_cpts_rft_clk";
        gpio0_dbclk_mux_ck = "/ocp/l4_wkup@44c00000/prcm@200000/clocks/gpio0_dbclk_mux_ck";
        gpio0_dbclk = "/ocp/l4_wkup@44c00000/prcm@200000/clocks/gpio0_dbclk";
        gpio1_dbclk = "/ocp/l4_wkup@44c00000/prcm@200000/clocks/gpio1_dbclk";
        gpio2_dbclk = "/ocp/l4_wkup@44c00000/prcm@200000/clocks/gpio2_dbclk";
        gpio3_dbclk = "/ocp/l4_wkup@44c00000/prcm@200000/clocks/gpio3_dbclk";
        lcd_gclk = "/ocp/l4_wkup@44c00000/prcm@200000/clocks/lcd_gclk";
        mmc_clk = "/ocp/l4_wkup@44c00000/prcm@200000/clocks/mmc_clk";
        gfx_fclk_clksel_ck = "/ocp/l4_wkup@44c00000/prcm@200000/clocks/gfx_fclk_clksel_ck";
        gfx_fck_div_ck = "/ocp/l4_wkup@44c00000/prcm@200000/clocks/gfx_fck_div_ck";
        sysclkout_pre_ck = "/ocp/l4_wkup@44c00000/prcm@200000/clocks/sysclkout_pre_ck";
        clkout2_div_ck = "/ocp/l4_wkup@44c00000/prcm@200000/clocks/clkout2_div_ck";
        dbg_sysclk_ck = "/ocp/l4_wkup@44c00000/prcm@200000/clocks/dbg_sysclk_ck";
        dbg_clka_ck = "/ocp/l4_wkup@44c00000/prcm@200000/clocks/dbg_clka_ck";
        stm_pmd_clock_mux_ck = "/ocp/l4_wkup@44c00000/prcm@200000/clocks/stm_pmd_clock_mux_ck";
        trace_pmd_clk_mux_ck = "/ocp/l4_wkup@44c00000/prcm@200000/clocks/trace_pmd_clk_mux_ck";
        stm_clk_div_ck = "/ocp/l4_wkup@44c00000/prcm@200000/clocks/stm_clk_div_ck";
        trace_clk_div_ck = "/ocp/l4_wkup@44c00000/prcm@200000/clocks/trace_clk_div_ck";
        clkout2_ck = "/ocp/l4_wkup@44c00000/prcm@200000/clocks/clkout2_ck";
        prcm_clockdomains = "/ocp/l4_wkup@44c00000/prcm@200000/clockdomains";
        clk_24mhz_clkdm = "/ocp/l4_wkup@44c00000/prcm@200000/clockdomains/clk_24mhz_clkdm";
        scm = "/ocp/l4_wkup@44c00000/scm@210000";
        am33xx_pinmux = "/ocp/l4_wkup@44c00000/scm@210000/pinmux@800";
        user_leds_default = "/ocp/l4_wkup@44c00000/scm@210000/pinmux@800/user_leds_default";
        user_leds_sleep = "/ocp/l4_wkup@44c00000/scm@210000/pinmux@800/user_leds_sleep";
        i2c0_pins = "/ocp/l4_wkup@44c00000/scm@210000/pinmux@800/pinmux_i2c0_pins";
        i2c2_pins = "/ocp/l4_wkup@44c00000/scm@210000/pinmux@800/pinmux_i2c2_pins";
        uart0_pins = "/ocp/l4_wkup@44c00000/scm@210000/pinmux@800/pinmux_uart0_pins";
        cpsw_default = "/ocp/l4_wkup@44c00000/scm@210000/pinmux@800/cpsw_default";
        cpsw_sleep = "/ocp/l4_wkup@44c00000/scm@210000/pinmux@800/cpsw_sleep";
        davinci_mdio_default = "/ocp/l4_wkup@44c00000/scm@210000/pinmux@800/davinci_mdio_default";
        davinci_mdio_sleep = "/ocp/l4_wkup@44c00000/scm@210000/pinmux@800/davinci_mdio_sleep";
        mmc1_pins = "/ocp/l4_wkup@44c00000/scm@210000/pinmux@800/pinmux_mmc1_pins";
        emmc_pins = "/ocp/l4_wkup@44c00000/scm@210000/pinmux@800/pinmux_emmc_pins";
        scm_conf = "/ocp/l4_wkup@44c00000/scm@210000/scm_conf@0";
        scm_clocks = "/ocp/l4_wkup@44c00000/scm@210000/scm_conf@0/clocks";
        sys_clkin_ck = "/ocp/l4_wkup@44c00000/scm@210000/scm_conf@0/clocks/sys_clkin_ck";
        adc_tsc_fck = "/ocp/l4_wkup@44c00000/scm@210000/scm_conf@0/clocks/adc_tsc_fck";
        dcan0_fck = "/ocp/l4_wkup@44c00000/scm@210000/scm_conf@0/clocks/dcan0_fck";
        dcan1_fck = "/ocp/l4_wkup@44c00000/scm@210000/scm_conf@0/clocks/dcan1_fck";
        mcasp0_fck = "/ocp/l4_wkup@44c00000/scm@210000/scm_conf@0/clocks/mcasp0_fck";
        mcasp1_fck = "/ocp/l4_wkup@44c00000/scm@210000/scm_conf@0/clocks/mcasp1_fck";
        smartreflex0_fck = "/ocp/l4_wkup@44c00000/scm@210000/scm_conf@0/clocks/smartreflex0_fck";
        smartreflex1_fck = "/ocp/l4_wkup@44c00000/scm@210000/scm_conf@0/clocks/smartreflex1_fck";
        sha0_fck = "/ocp/l4_wkup@44c00000/scm@210000/scm_conf@0/clocks/sha0_fck";
        aes0_fck = "/ocp/l4_wkup@44c00000/scm@210000/scm_conf@0/clocks/aes0_fck";
        rng_fck = "/ocp/l4_wkup@44c00000/scm@210000/scm_conf@0/clocks/rng_fck";
        ehrpwm0_tbclk = "/ocp/l4_wkup@44c00000/scm@210000/scm_conf@0/clocks/ehrpwm0_tbclk@44e10664";
        ehrpwm1_tbclk = "/ocp/l4_wkup@44c00000/scm@210000/scm_conf@0/clocks/ehrpwm1_tbclk@44e10664";
        ehrpwm2_tbclk = "/ocp/l4_wkup@44c00000/scm@210000/scm_conf@0/clocks/ehrpwm2_tbclk@44e10664";
        wkup_m3_ipc = "/ocp/l4_wkup@44c00000/scm@210000/wkup_m3_ipc@1324";
        edma_xbar = "/ocp/l4_wkup@44c00000/scm@210000/dma-router@f90";
        scm_clockdomains = "/ocp/l4_wkup@44c00000/scm@210000/clockdomains";
        intc = "/ocp/interrupt-controller@48200000";
        edma = "/ocp/edma@49000000";
        edma_tptc0 = "/ocp/tptc@49800000";
        edma_tptc1 = "/ocp/tptc@49900000";
        edma_tptc2 = "/ocp/tptc@49a00000";
        emif = "/ocp/emif@4c000000";
        gpio0 = "/ocp/gpio@44e07000";
        gpio1 = "/ocp/gpio@4804c000";
        gpio2 = "/ocp/gpio@481ac000";
        gpio3 = "/ocp/gpio@481ae000";
        uart0 = "/ocp/serial@44e09000";
        uart1 = "/ocp/serial@48022000";
        uart2 = "/ocp/serial@48024000";
        uart3 = "/ocp/serial@481a6000";
        uart4 = "/ocp/serial@481a8000";
        uart5 = "/ocp/serial@481aa000";
        i2c0 = "/ocp/i2c@44e0b000";
        tps = "/ocp/i2c@44e0b000/tps@24";
        dcdc1_reg = "/ocp/i2c@44e0b000/tps@24/regulators/regulator@0";
        dcdc2_reg = "/ocp/i2c@44e0b000/tps@24/regulators/regulator@1";
        dcdc3_reg = "/ocp/i2c@44e0b000/tps@24/regulators/regulator@2";
        ldo1_reg = "/ocp/i2c@44e0b000/tps@24/regulators/regulator@3";
        ldo2_reg = "/ocp/i2c@44e0b000/tps@24/regulators/regulator@4";
        ldo3_reg = "/ocp/i2c@44e0b000/tps@24/regulators/regulator@5";
        ldo4_reg = "/ocp/i2c@44e0b000/tps@24/regulators/regulator@6";
        baseboard_eeprom = "/ocp/i2c@44e0b000/baseboard_eeprom@50";
        baseboard_data = "/ocp/i2c@44e0b000/baseboard_eeprom@50/baseboard_data@0";
        i2c1 = "/ocp/i2c@4802a000";
        i2c2 = "/ocp/i2c@4819c000";
        cape_eeprom0 = "/ocp/i2c@4819c000/cape_eeprom0@54";
        cape0_data = "/ocp/i2c@4819c000/cape_eeprom0@54/cape_data@0";
        cape_eeprom1 = "/ocp/i2c@4819c000/cape_eeprom1@55";
        cape1_data = "/ocp/i2c@4819c000/cape_eeprom1@55/cape_data@0";
        cape_eeprom2 = "/ocp/i2c@4819c000/cape_eeprom2@56";
        cape2_data = "/ocp/i2c@4819c000/cape_eeprom2@56/cape_data@0";
        cape_eeprom3 = "/ocp/i2c@4819c000/cape_eeprom3@57";
        cape3_data = "/ocp/i2c@4819c000/cape_eeprom3@57/cape_data@0";
        mmc1 = "/ocp/mmc@48060000";
        mmc2 = "/ocp/mmc@481d8000";
        mmc3 = "/ocp/mmc@47810000";
        hwspinlock = "/ocp/spinlock@480ca000";
        wdt2 = "/ocp/wdt@44e35000";
        dcan0 = "/ocp/can@481cc000";
        dcan1 = "/ocp/can@481d0000";
        mailbox = "/ocp/mailbox@480C8000";
        mbox_wkupm3 = "/ocp/mailbox@480C8000/wkup_m3";
        mbox_pru0 = "/ocp/mailbox@480C8000/mbox_pru0";
        mbox_pru1 = "/ocp/mailbox@480C8000/mbox_pru1";
        timer1 = "/ocp/timer@44e31000";
        timer2 = "/ocp/timer@48040000";
        timer3 = "/ocp/timer@48042000";
        timer4 = "/ocp/timer@48044000";
        timer5 = "/ocp/timer@48046000";
        timer6 = "/ocp/timer@48048000";
        timer7 = "/ocp/timer@4804a000";
        rtc = "/ocp/rtc@44e3e000";
        spi0 = "/ocp/spi@48030000";
        spi1 = "/ocp/spi@481a0000";
        usb = "/ocp/usb@47400000";
        usb_ctrl_mod = "/ocp/usb@47400000/control@44e10620";
        usb0_phy = "/ocp/usb@47400000/usb-phy@47401300";
        usb0 = "/ocp/usb@47400000/usb@47401000";
        usb1_phy = "/ocp/usb@47400000/usb-phy@47401b00";
        usb1 = "/ocp/usb@47400000/usb@47401800";
        cppi41dma = "/ocp/usb@47400000/dma-controller@47402000";
        epwmss0 = "/ocp/epwmss@48300000";
        ecap0 = "/ocp/epwmss@48300000/ecap@48300100";
        eqep0 = "/ocp/epwmss@48300000/eqep@0x48300180";
        ehrpwm0 = "/ocp/epwmss@48300000/pwm@48300200";
        epwmss1 = "/ocp/epwmss@48302000";
        ecap1 = "/ocp/epwmss@48302000/ecap@48302100";
        eqep1 = "/ocp/epwmss@48302000/eqep@0x48302180";
        ehrpwm1 = "/ocp/epwmss@48302000/pwm@48302200";
        epwmss2 = "/ocp/epwmss@48304000";
        ecap2 = "/ocp/epwmss@48304000/ecap@48304100";
        eqep2 = "/ocp/epwmss@48304000/eqep@0x48304180";
        ehrpwm2 = "/ocp/epwmss@48304000/pwm@48304200";
        mac = "/ocp/ethernet@4a100000";
        davinci_mdio = "/ocp/ethernet@4a100000/mdio@4a101000";
        cpsw_emac0 = "/ocp/ethernet@4a100000/slave@4a100200";
        cpsw_emac1 = "/ocp/ethernet@4a100000/slave@4a100300";
        phy_sel = "/ocp/ethernet@4a100000/cpsw-phy-sel@44e10650";
        ocmcram = "/ocp/ocmcram@40300000";
        ocmcram_nocache = "/ocp/ocmcram_nocache@40302000";
        pruss = "/ocp/pruss@4a300000";
        pruss_intc = "/ocp/pruss@4a300000/intc@4a320000";
        pru0 = "/ocp/pruss@4a300000/pru0@4a334000";
        pru1 = "/ocp/pruss@4a300000/pru1@4a338000";
        pruss_mdio = "/ocp/pruss@4a300000/mdio@4a332400";
        elm = "/ocp/elm@48080000";
        lcdc = "/ocp/lcdc@4830e000";
        tscadc = "/ocp/tscadc@44e0d000";
        am335x_adc = "/ocp/tscadc@44e0d000/adc";
        gpmc = "/ocp/gpmc@50000000";
        sham = "/ocp/sham@53100000";
        aes = "/ocp/aes@53500000";
        mcasp0 = "/ocp/mcasp@48038000";
        mcasp1 = "/ocp/mcasp@4803C000";
        rng = "/ocp/rng@48310000";
        sgx = "/ocp/sgx@56000000";
        vmmcsd_fixed = "/fixedregulator@0";
        baseboard_beaglebone = "/bone_capemgr/baseboardmaps/board@0";
        baseboard_beaglebone_black = "/bone_capemgr/baseboardmaps/board@1";
    };
};
